VERSION "1.0.0"

NS_ :

BS_:

BU_: CVC FZC RZC SC BCM ICU TCU Diag

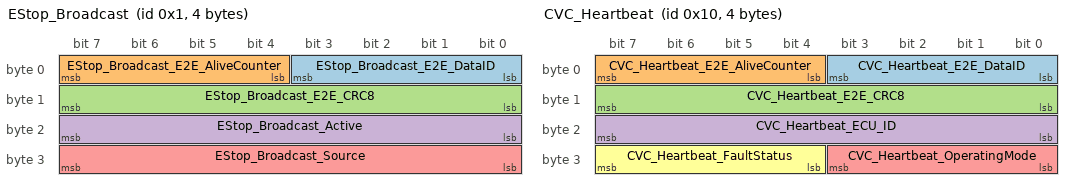
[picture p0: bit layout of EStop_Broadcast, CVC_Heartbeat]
BO_ 1 EStop_Broadcast: 4 CVC
 SG_ EStop_Broadcast_E2E_DataID : 0|4@1+ (1,0) [0|15] "" SC,FZC,RZC,BCM,ICU,TCU
 SG_ EStop_Broadcast_E2E_AliveCounter : 4|4@1+ (1,0) [0|15] "" SC,FZC,RZC,BCM,ICU,TCU
 SG_ EStop_Broadcast_E2E_CRC8 : 8|8@1+ (1,0) [0|255] "" SC,FZC,RZC,BCM,ICU,TCU
 SG_ EStop_Broadcast_Active : 16|8@1+ (1,0) [0|1] "" SC,FZC,RZC,BCM,ICU
 SG_ EStop_Broadcast_Source : 24|8@1+ (1,0) [0|7] "" SC,FZC,RZC,BCM,ICU

BO_ 16 CVC_Heartbeat: 4 CVC
 SG_ CVC_Heartbeat_E2E_DataID : 0|4@1+ (1,0) [0|15] "" SC,FZC,RZC,ICU
 SG_ CVC_Heartbeat_E2E_AliveCounter : 4|4@1+ (1,0) [0|15] "" SC,FZC,RZC,ICU
 SG_ CVC_Heartbeat_E2E_CRC8 : 8|8@1+ (1,0) [0|255] "" SC,FZC,RZC,ICU
 SG_ CVC_Heartbeat_ECU_ID : 16|8@1+ (1,0) [0|7] "" SC,FZC,RZC,ICU
 SG_ CVC_Heartbeat_OperatingMode : 24|4@1+ (1,0) [0|5] "" SC,FZC,RZC,ICU
 SG_ CVC_Heartbeat_FaultStatus : 28|4@1+ (1,0) [0|15] "" SC,FZC,RZC,ICU

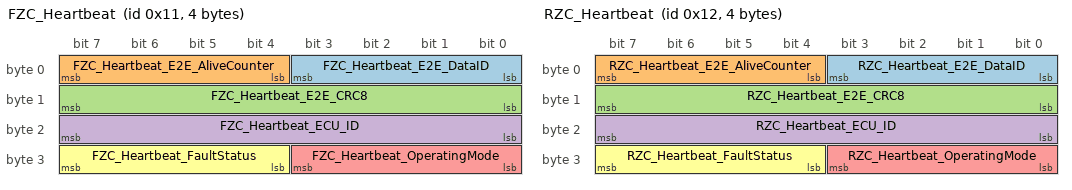
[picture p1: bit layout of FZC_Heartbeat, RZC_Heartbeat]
BO_ 17 FZC_Heartbeat: 4 FZC
 SG_ FZC_Heartbeat_E2E_DataID : 0|4@1+ (1,0) [0|15] "" SC,CVC,ICU
 SG_ FZC_Heartbeat_E2E_AliveCounter : 4|4@1+ (1,0) [0|15] "" SC,CVC,ICU
 SG_ FZC_Heartbeat_E2E_CRC8 : 8|8@1+ (1,0) [0|255] "" SC,CVC,ICU
 SG_ FZC_Heartbeat_ECU_ID : 16|8@1+ (1,0) [0|7] "" SC,CVC,ICU
 SG_ FZC_Heartbeat_OperatingMode : 24|4@1+ (1,0) [0|5] "" SC,CVC,ICU
 SG_ FZC_Heartbeat_FaultStatus : 28|4@1+ (1,0) [0|15] "" SC,CVC,ICU

BO_ 18 RZC_Heartbeat: 4 RZC
 SG_ RZC_Heartbeat_E2E_DataID : 0|4@1+ (1,0) [0|15] "" SC,CVC,ICU
 SG_ RZC_Heartbeat_E2E_AliveCounter : 4|4@1+ (1,0) [0|15] "" SC,CVC,ICU
 SG_ RZC_Heartbeat_E2E_CRC8 : 8|8@1+ (1,0) [0|255] "" SC,CVC,ICU
 SG_ RZC_Heartbeat_ECU_ID : 16|8@1+ (1,0) [0|7] "" SC,CVC,ICU
 SG_ RZC_Heartbeat_OperatingMode : 24|4@1+ (1,0) [0|5] "" SC,CVC,ICU
 SG_ RZC_Heartbeat_FaultStatus : 28|4@1+ (1,0) [0|15] "" SC,CVC,ICU

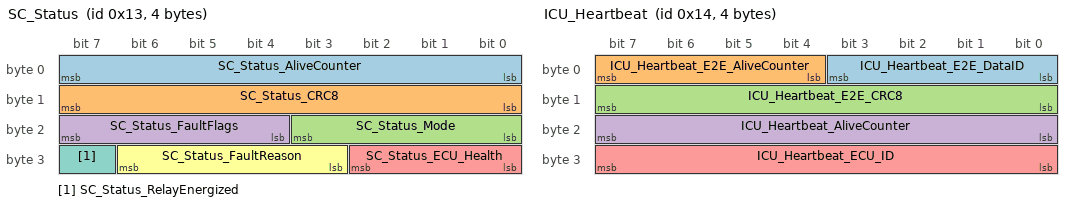
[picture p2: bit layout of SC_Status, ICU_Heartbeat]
BO_ 19 SC_Status: 4 SC
 SG_ SC_Status_AliveCounter : 0|8@1+ (1,0) [0|255] "" CVC,FZC,RZC,ICU
 SG_ SC_Status_CRC8 : 8|8@1+ (1,0) [0|255] "" CVC,FZC,RZC,ICU
 SG_ SC_Status_Mode : 16|4@1+ (1,0) [0|3] "" CVC,FZC,RZC,ICU
 SG_ SC_Status_FaultFlags : 20|4@1+ (1,0) [0|15] "" CVC,FZC,RZC,ICU
 SG_ SC_Status_ECU_Health : 24|3@1+ (1,0) [0|7] "" CVC,FZC,RZC,ICU
 SG_ SC_Status_FaultReason : 27|4@1+ (1,0) [0|15] "" CVC,FZC,RZC,ICU
 SG_ SC_Status_RelayEnergized : 31|1@1+ (1,0) [0|1] "" CVC,FZC,RZC,ICU

BO_ 20 ICU_Heartbeat: 4 ICU
 SG_ ICU_Heartbeat_E2E_DataID : 0|4@1+ (1,0) [0|15] "" CVC
 SG_ ICU_Heartbeat_E2E_AliveCounter : 4|4@1+ (1,0) [0|15] "" CVC
 SG_ ICU_Heartbeat_E2E_CRC8 : 8|8@1+ (1,0) [0|255] "" CVC
 SG_ ICU_Heartbeat_AliveCounter : 16|8@1+ (1,0) [0|255] "" CVC
 SG_ ICU_Heartbeat_ECU_ID : 24|8@1+ (1,0) [0|7] "" CVC

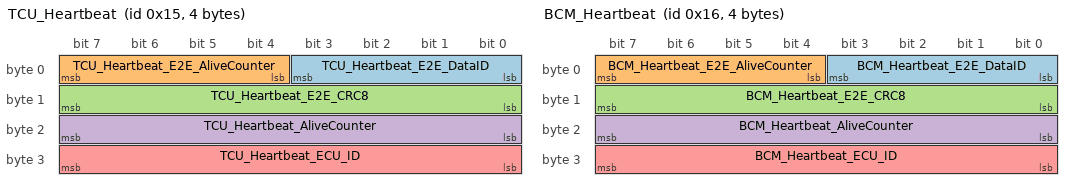
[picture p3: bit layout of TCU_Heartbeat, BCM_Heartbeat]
BO_ 21 TCU_Heartbeat: 4 TCU
 SG_ TCU_Heartbeat_E2E_DataID : 0|4@1+ (1,0) [0|15] "" CVC
 SG_ TCU_Heartbeat_E2E_AliveCounter : 4|4@1+ (1,0) [0|15] "" CVC
 SG_ TCU_Heartbeat_E2E_CRC8 : 8|8@1+ (1,0) [0|255] "" CVC
 SG_ TCU_Heartbeat_AliveCounter : 16|8@1+ (1,0) [0|255] "" CVC
 SG_ TCU_Heartbeat_ECU_ID : 24|8@1+ (1,0) [0|7] "" CVC

BO_ 22 BCM_Heartbeat: 4 BCM
 SG_ BCM_Heartbeat_E2E_DataID : 0|4@1+ (1,0) [0|15] "" CVC,ICU
 SG_ BCM_Heartbeat_E2E_AliveCounter : 4|4@1+ (1,0) [0|15] "" CVC,ICU
 SG_ BCM_Heartbeat_E2E_CRC8 : 8|8@1+ (1,0) [0|255] "" CVC,ICU
 SG_ BCM_Heartbeat_AliveCounter : 16|8@1+ (1,0) [0|255] "" CVC,ICU
 SG_ BCM_Heartbeat_ECU_ID : 24|8@1+ (1,0) [0|7] "" CVC,ICU

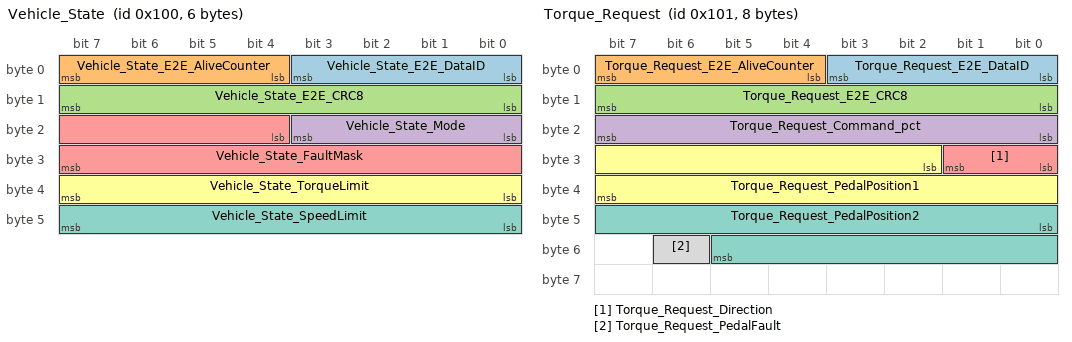
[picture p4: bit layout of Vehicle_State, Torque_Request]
BO_ 256 Vehicle_State: 6 CVC
 SG_ Vehicle_State_E2E_DataID : 0|4@1+ (1,0) [0|15] "" FZC,RZC,BCM,ICU,SC
 SG_ Vehicle_State_E2E_AliveCounter : 4|4@1+ (1,0) [0|15] "" FZC,RZC,BCM,ICU,SC
 SG_ Vehicle_State_E2E_CRC8 : 8|8@1+ (1,0) [0|255] "" FZC,RZC,BCM,ICU,SC
 SG_ Vehicle_State_Mode : 16|4@1+ (1,0) [0|5] "" FZC,RZC,BCM,ICU,SC
 SG_ Vehicle_State_FaultMask : 20|12@1+ (1,0) [0|4095] "" FZC,RZC,BCM,ICU,SC
 SG_ Vehicle_State_TorqueLimit : 32|8@1+ (1,0) [0|100] "%" RZC,ICU
 SG_ Vehicle_State_SpeedLimit : 40|8@1+ (1,0) [0|100] "%" RZC,ICU

BO_ 257 Torque_Request: 8 CVC
 SG_ Torque_Request_E2E_DataID : 0|4@1+ (1,0) [0|15] "" RZC
 SG_ Torque_Request_E2E_AliveCounter : 4|4@1+ (1,0) [0|15] "" RZC
 SG_ Torque_Request_E2E_CRC8 : 8|8@1+ (1,0) [0|255] "" RZC
 SG_ Torque_Request_Command_pct : 16|8@1+ (1,0) [0|100] "%" RZC
 SG_ Torque_Request_Direction : 24|2@1+ (1,0) [0|2] "" RZC
 SG_ Torque_Request_PedalPosition1 : 26|14@1+ (0.022,0) [0|359.98] "deg" RZC
 SG_ Torque_Request_PedalPosition2 : 40|14@1+ (0.022,0) [0|359.98] "deg" RZC
 SG_ Torque_Request_PedalFault : 54|1@1+ (1,0) [0|1] "" RZC

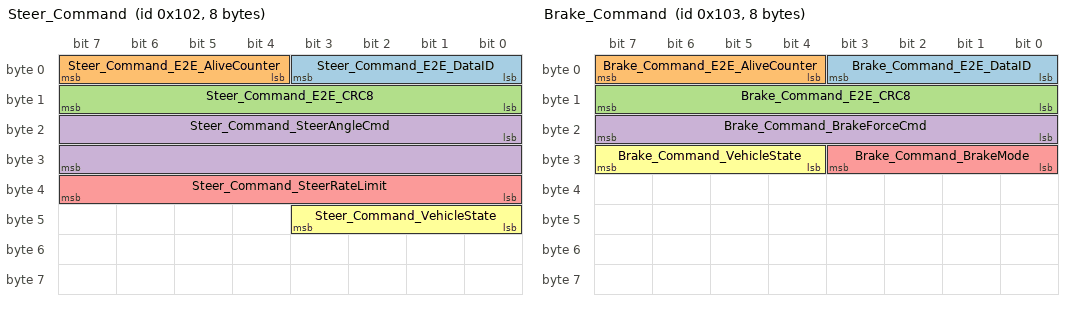
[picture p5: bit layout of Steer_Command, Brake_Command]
BO_ 258 Steer_Command: 8 CVC
 SG_ Steer_Command_E2E_DataID : 0|4@1+ (1,0) [0|15] "" FZC
 SG_ Steer_Command_E2E_AliveCounter : 4|4@1+ (1,0) [0|15] "" FZC
 SG_ Steer_Command_E2E_CRC8 : 8|8@1+ (1,0) [0|255] "" FZC
 SG_ Steer_Command_SteerAngleCmd : 16|16@1- (0.01,0) [-45.0|45.0] "deg" FZC
 SG_ Steer_Command_SteerRateLimit : 32|8@1+ (0.2,0) [0|51.0] "deg/s" FZC
 SG_ Steer_Command_VehicleState : 40|4@1+ (1,0) [0|5] "" FZC

BO_ 259 Brake_Command: 8 CVC
 SG_ Brake_Command_E2E_DataID : 0|4@1+ (1,0) [0|15] "" FZC
 SG_ Brake_Command_E2E_AliveCounter : 4|4@1+ (1,0) [0|15] "" FZC
 SG_ Brake_Command_E2E_CRC8 : 8|8@1+ (1,0) [0|255] "" FZC
 SG_ Brake_Command_BrakeForceCmd : 16|8@1+ (1,0) [0|100] "%" FZC
 SG_ Brake_Command_BrakeMode : 24|4@1+ (1,0) [0|3] "" FZC
 SG_ Brake_Command_VehicleState : 28|4@1+ (1,0) [0|5] "" FZC

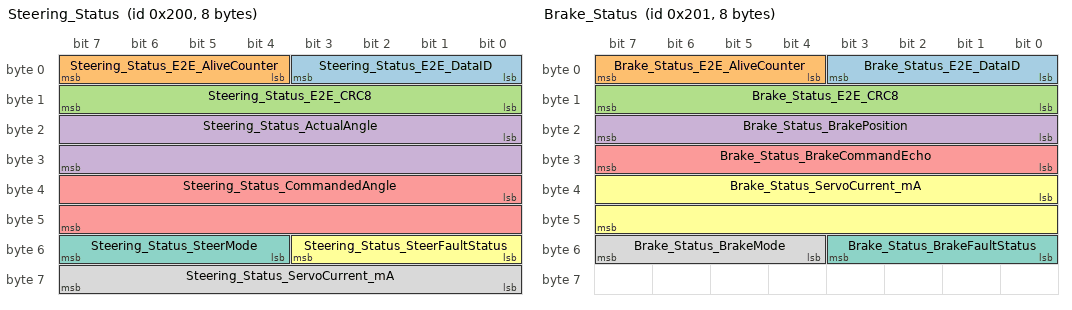
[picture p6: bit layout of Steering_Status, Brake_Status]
BO_ 512 Steering_Status: 8 FZC
 SG_ Steering_Status_E2E_DataID : 0|4@1+ (1,0) [0|15] "" CVC,SC,ICU
 SG_ Steering_Status_E2E_AliveCounter : 4|4@1+ (1,0) [0|15] "" CVC,SC,ICU
 SG_ Steering_Status_E2E_CRC8 : 8|8@1+ (1,0) [0|255] "" CVC,SC,ICU
 SG_ Steering_Status_ActualAngle : 16|16@1- (1,0) [-45|45] "deg" CVC,SC,ICU
 SG_ Steering_Status_CommandedAngle : 32|16@1- (1,0) [-45|45] "deg" CVC,SC,ICU
 SG_ Steering_Status_SteerFaultStatus : 48|4@1+ (1,0) [0|15] "" CVC,SC,ICU
 SG_ Steering_Status_SteerMode : 52|4@1+ (1,0) [0|3] "" CVC,SC,ICU
 SG_ Steering_Status_ServoCurrent_mA : 56|8@1+ (10,0) [0|2550] "mA" CVC,SC,ICU

BO_ 513 Brake_Status: 8 FZC
 SG_ Brake_Status_E2E_DataID : 0|4@1+ (1,0) [0|15] "" CVC,SC,ICU
 SG_ Brake_Status_E2E_AliveCounter : 4|4@1+ (1,0) [0|15] "" CVC,SC,ICU
 SG_ Brake_Status_E2E_CRC8 : 8|8@1+ (1,0) [0|255] "" CVC,SC,ICU
 SG_ Brake_Status_BrakePosition : 16|8@1+ (1,0) [0|100] "%" CVC,SC,ICU
 SG_ Brake_Status_BrakeCommandEcho : 24|8@1+ (1,0) [0|100] "%" CVC,SC,ICU
 SG_ Brake_Status_ServoCurrent_mA : 32|16@1+ (1,0) [0|3000] "mA" CVC,SC,ICU
 SG_ Brake_Status_BrakeFaultStatus : 48|4@1+ (1,0) [0|15] "" CVC,SC,ICU
 SG_ Brake_Status_BrakeMode : 52|4@1+ (1,0) [0|3] "" CVC,SC,ICU

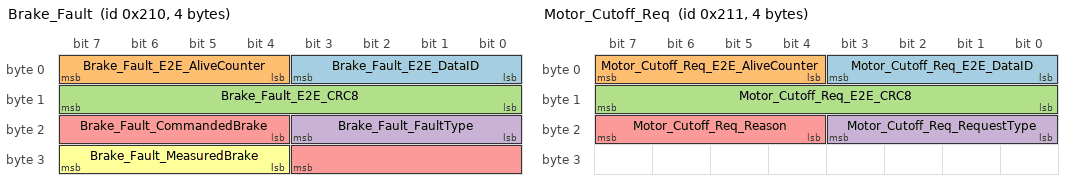
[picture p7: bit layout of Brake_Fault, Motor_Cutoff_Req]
BO_ 528 Brake_Fault: 4 FZC
 SG_ Brake_Fault_E2E_DataID : 0|4@1+ (1,0) [0|15] "" CVC,SC
 SG_ Brake_Fault_E2E_AliveCounter : 4|4@1+ (1,0) [0|15] "" CVC,SC
 SG_ Brake_Fault_E2E_CRC8 : 8|8@1+ (1,0) [0|255] "" CVC,SC
 SG_ Brake_Fault_FaultType : 16|4@1+ (1,0) [0|3] "" CVC,SC
 SG_ Brake_Fault_CommandedBrake : 20|8@1+ (1,0) [0|100] "%" CVC,SC
 SG_ Brake_Fault_MeasuredBrake : 28|4@1+ (10,0) [0|100] "%" CVC,SC

BO_ 529 Motor_Cutoff_Req: 4 FZC
 SG_ Motor_Cutoff_Req_E2E_DataID : 0|4@1+ (1,0) [0|15] "" CVC
 SG_ Motor_Cutoff_Req_E2E_AliveCounter : 4|4@1+ (1,0) [0|15] "" CVC
 SG_ Motor_Cutoff_Req_E2E_CRC8 : 8|8@1+ (1,0) [0|255] "" CVC
 SG_ Motor_Cutoff_Req_RequestType : 16|4@1+ (1,0) [0|3] "" CVC
 SG_ Motor_Cutoff_Req_Reason : 20|4@1+ (1,0) [0|7] "" CVC

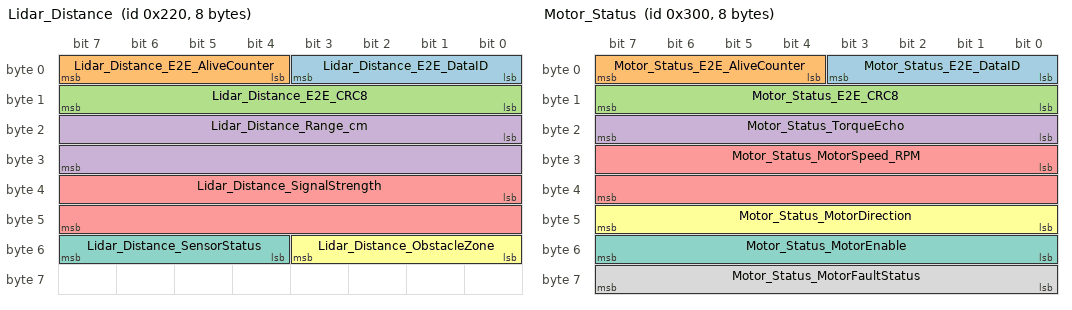
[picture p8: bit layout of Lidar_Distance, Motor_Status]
BO_ 544 Lidar_Distance: 8 FZC
 SG_ Lidar_Distance_E2E_DataID : 0|4@1+ (1,0) [0|15] "" CVC,ICU
 SG_ Lidar_Distance_E2E_AliveCounter : 4|4@1+ (1,0) [0|15] "" CVC,ICU
 SG_ Lidar_Distance_E2E_CRC8 : 8|8@1+ (1,0) [0|255] "" CVC,ICU
 SG_ Lidar_Distance_Range_cm : 16|16@1+ (1,0) [0|1200] "cm" CVC,ICU
 SG_ Lidar_Distance_SignalStrength : 32|16@1+ (1,0) [0|65535] "" CVC,ICU
 SG_ Lidar_Distance_ObstacleZone : 48|4@1+ (1,0) [0|3] "" CVC,ICU
 SG_ Lidar_Distance_SensorStatus : 52|4@1+ (1,0) [0|15] "" CVC,ICU

BO_ 768 Motor_Status: 8 RZC
 SG_ Motor_Status_E2E_DataID : 0|4@1+ (1,0) [0|15] "" CVC,SC,ICU
 SG_ Motor_Status_E2E_AliveCounter : 4|4@1+ (1,0) [0|15] "" CVC,SC,ICU
 SG_ Motor_Status_E2E_CRC8 : 8|8@1+ (1,0) [0|255] "" CVC,SC,ICU
 SG_ Motor_Status_TorqueEcho : 16|8@1+ (1,0) [0|100] "%" CVC,SC,ICU
 SG_ Motor_Status_MotorSpeed_RPM : 24|16@1+ (1,0) [0|10000] "RPM" CVC,SC,ICU
 SG_ Motor_Status_MotorDirection : 40|8@1+ (1,0) [0|2] "" CVC,SC,ICU
 SG_ Motor_Status_MotorEnable : 48|8@1+ (1,0) [0|1] "" CVC,SC,ICU
 SG_ Motor_Status_MotorFaultStatus : 56|8@1+ (1,0) [0|31] "" CVC,SC,ICU

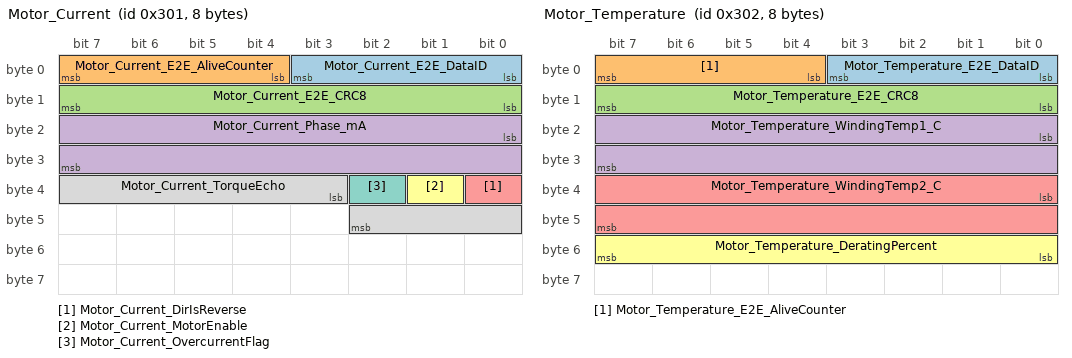
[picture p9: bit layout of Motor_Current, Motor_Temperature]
BO_ 769 Motor_Current: 8 RZC
 SG_ Motor_Current_E2E_DataID : 0|4@1+ (1,0) [0|15] "" SC,CVC,ICU
 SG_ Motor_Current_E2E_AliveCounter : 4|4@1+ (1,0) [0|15] "" SC,CVC,ICU
 SG_ Motor_Current_E2E_CRC8 : 8|8@1+ (1,0) [0|255] "" SC,CVC,ICU
 SG_ Motor_Current_Phase_mA : 16|16@1+ (1,0) [0|30000] "mA" SC,CVC,ICU
 SG_ Motor_Current_DirIsReverse : 32|1@1+ (1,0) [0|1] "" SC,CVC,ICU
 SG_ Motor_Current_MotorEnable : 33|1@1+ (1,0) [0|1] "" SC,CVC,ICU
 SG_ Motor_Current_OvercurrentFlag : 34|1@1+ (1,0) [0|1] "" SC,CVC,ICU
 SG_ Motor_Current_TorqueEcho : 35|8@1+ (1,0) [0|100] "%" SC,CVC,ICU

BO_ 770 Motor_Temperature: 8 RZC
 SG_ Motor_Temperature_E2E_DataID : 0|4@1+ (1,0) [0|15] "" CVC,ICU
 SG_ Motor_Temperature_E2E_AliveCounter : 4|4@1+ (1,0) [0|15] "" CVC,ICU
 SG_ Motor_Temperature_E2E_CRC8 : 8|8@1+ (1,0) [0|255] "" CVC,ICU
 SG_ Motor_Temperature_WindingTemp1_C : 16|16@1+ (0.1,0) [0|200.0] "degC" CVC,ICU
 SG_ Motor_Temperature_WindingTemp2_C : 32|16@1+ (0.1,0) [0|200.0] "degC" CVC,ICU
 SG_ Motor_Temperature_DeratingPercent : 48|8@1+ (1,0) [0|100] "%" CVC,ICU

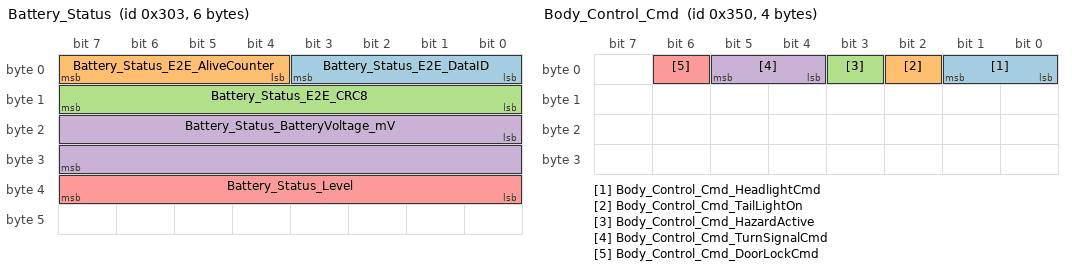
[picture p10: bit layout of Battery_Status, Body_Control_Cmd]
BO_ 771 Battery_Status: 6 RZC
 SG_ Battery_Status_E2E_DataID : 0|4@1+ (1,0) [0|15] "" CVC,ICU
 SG_ Battery_Status_E2E_AliveCounter : 4|4@1+ (1,0) [0|15] "" CVC,ICU
 SG_ Battery_Status_E2E_CRC8 : 8|8@1+ (1,0) [0|255] "" CVC,ICU
 SG_ Battery_Status_BatteryVoltage_mV : 16|16@1+ (1,0) [0|20000] "mV" CVC,ICU
 SG_ Battery_Status_Level : 32|8@1+ (1,0) [0|4] "" CVC,ICU

BO_ 848 Body_Control_Cmd: 4 CVC
 SG_ Body_Control_Cmd_HeadlightCmd : 0|2@1+ (1,0) [0|2] "" BCM
 SG_ Body_Control_Cmd_TailLightOn : 2|1@1+ (1,0) [0|1] "" BCM
 SG_ Body_Control_Cmd_HazardActive : 3|1@1+ (1,0) [0|1] "" BCM
 SG_ Body_Control_Cmd_TurnSignalCmd : 4|2@1+ (1,0) [0|2] "" BCM
 SG_ Body_Control_Cmd_DoorLockCmd : 6|1@1+ (1,0) [0|1] "" BCM

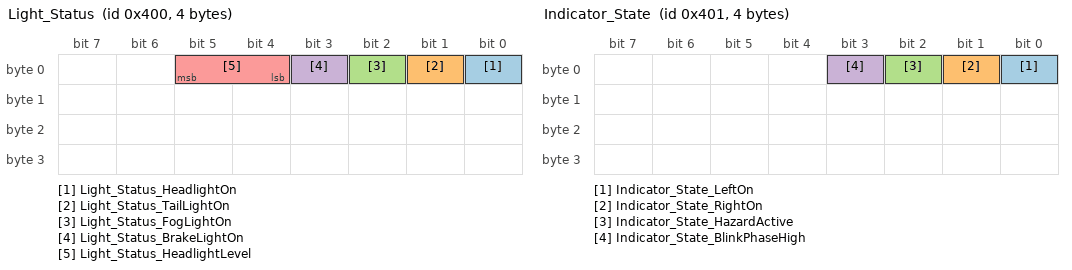
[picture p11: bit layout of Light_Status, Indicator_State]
BO_ 1024 Light_Status: 4 BCM
 SG_ Light_Status_HeadlightOn : 0|1@1+ (1,0) [0|1] "" ICU
 SG_ Light_Status_TailLightOn : 1|1@1+ (1,0) [0|1] "" ICU
 SG_ Light_Status_FogLightOn : 2|1@1+ (1,0) [0|1] "" ICU
 SG_ Light_Status_BrakeLightOn : 3|1@1+ (1,0) [0|1] "" ICU
 SG_ Light_Status_HeadlightLevel : 4|2@1+ (1,0) [0|2] "" ICU

BO_ 1025 Indicator_State: 4 BCM
 SG_ Indicator_State_LeftOn : 0|1@1+ (1,0) [0|1] "" ICU
 SG_ Indicator_State_RightOn : 1|1@1+ (1,0) [0|1] "" ICU
 SG_ Indicator_State_HazardActive : 2|1@1+ (1,0) [0|1] "" ICU
 SG_ Indicator_State_BlinkPhaseHigh : 3|1@1+ (1,0) [0|1] "" ICU

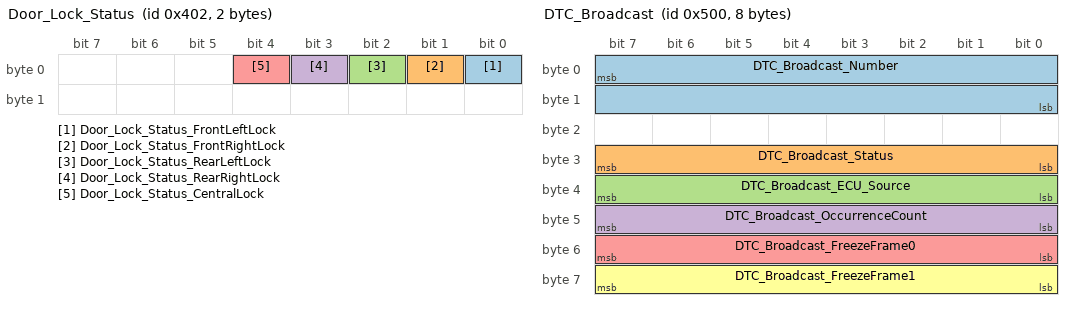
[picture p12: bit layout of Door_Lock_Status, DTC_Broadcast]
BO_ 1026 Door_Lock_Status: 2 BCM
 SG_ Door_Lock_Status_FrontLeftLock : 0|1@1+ (1,0) [0|1] "" ICU
 SG_ Door_Lock_Status_FrontRightLock : 1|1@1+ (1,0) [0|1] "" ICU
 SG_ Door_Lock_Status_RearLeftLock : 2|1@1+ (1,0) [0|1] "" ICU
 SG_ Door_Lock_Status_RearRightLock : 3|1@1+ (1,0) [0|1] "" ICU
 SG_ Door_Lock_Status_CentralLock : 4|1@1+ (1,0) [0|1] "" ICU

BO_ 1280 DTC_Broadcast: 8 CVC
 SG_ DTC_Broadcast_Number : 7|16@0+ (1,0) [0|65535] "" TCU,ICU
 SG_ DTC_Broadcast_Status : 24|8@1+ (1,0) [0|255] "" TCU,ICU
 SG_ DTC_Broadcast_ECU_Source : 32|8@1+ (1,0) [0|7] "" TCU,ICU
 SG_ DTC_Broadcast_OccurrenceCount : 40|8@1+ (1,0) [0|255] "" TCU,ICU
 SG_ DTC_Broadcast_FreezeFrame0 : 48|8@1+ (1,0) [0|255] "" TCU,ICU
 SG_ DTC_Broadcast_FreezeFrame1 : 56|8@1+ (1,0) [0|255] "" TCU,ICU

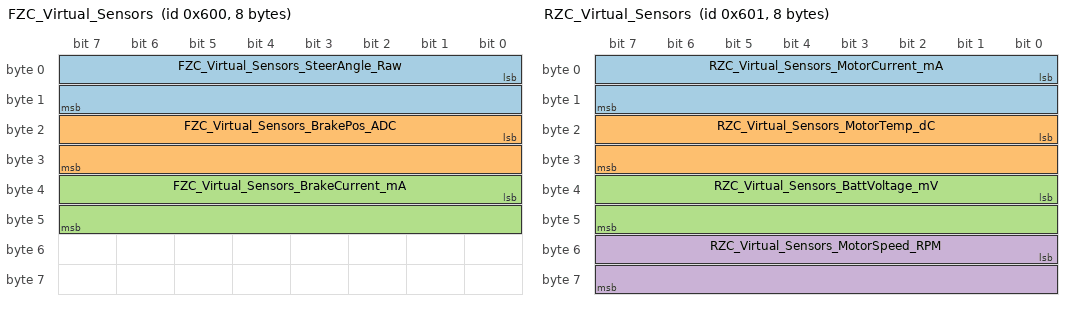
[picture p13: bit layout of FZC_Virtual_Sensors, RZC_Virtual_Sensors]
BO_ 1536 FZC_Virtual_Sensors: 8 CVC
 SG_ FZC_Virtual_Sensors_SteerAngle_Raw : 0|16@1+ (1,0) [0|16383] "" FZC
 SG_ FZC_Virtual_Sensors_BrakePos_ADC : 16|16@1+ (1,0) [0|1000] "" FZC
 SG_ FZC_Virtual_Sensors_BrakeCurrent_mA : 32|16@1+ (1,0) [0|65535] "mA" FZC

BO_ 1537 RZC_Virtual_Sensors: 8 CVC
 SG_ RZC_Virtual_Sensors_MotorCurrent_mA : 0|16@1+ (1,0) [0|65535] "mA" RZC
 SG_ RZC_Virtual_Sensors_MotorTemp_dC : 16|16@1+ (1,0) [0|2000] "" RZC
 SG_ RZC_Virtual_Sensors_BattVoltage_mV : 32|16@1+ (1,0) [0|20000] "mV" RZC
 SG_ RZC_Virtual_Sensors_MotorSpeed_RPM : 48|16@1+ (1,0) [0|10000] "rpm" RZC

BO_ 1604 UDS_Resp_TCU: 8 TCU
 SG_ UDS_Resp_TCU_UDS_Data : 0|64@1+ (1,0) [0|0] "" Diag

BO_ 2015 UDS_Func_Request: 8 Diag
 SG_ UDS_Func_Request_UDS_Data : 0|64@1+ (1,0) [0|0] "" CVC,FZC,RZC,TCU,BCM,ICU

BO_ 2016 UDS_Phys_Req_CVC: 8 Diag
 SG_ UDS_Phys_Req_CVC_UDS_Data : 0|64@1+ (1,0) [0|0] "" CVC

BO_ 2017 UDS_Phys_Req_FZC: 8 Diag
 SG_ UDS_Phys_Req_FZC_UDS_Data : 0|64@1+ (1,0) [0|0] "" FZC

BO_ 2018 UDS_Phys_Req_RZC: 8 Diag
 SG_ UDS_Phys_Req_RZC_UDS_Data : 0|64@1+ (1,0) [0|0] "" RZC

BO_ 2019 UDS_Phys_Req_TCU: 8 Diag
 SG_ UDS_Phys_Req_TCU_UDS_Data : 0|64@1+ (1,0) [0|0] "" TCU

BO_ 2024 UDS_Resp_CVC: 8 CVC
 SG_ UDS_Resp_CVC_UDS_Data : 0|64@1+ (1,0) [0|0] "" Diag

BO_ 2025 UDS_Resp_FZC: 8 FZC
 SG_ UDS_Resp_FZC_UDS_Data : 0|64@1+ (1,0) [0|0] "" Diag

BO_ 2026 UDS_Resp_RZC: 8 RZC
 SG_ UDS_Resp_RZC_UDS_Data : 0|64@1+ (1,0) [0|0] "" Diag

BO_ 1360 XCP_Req_CVC: 8 Diag
 SG_ XCP_Req_CVC_Data : 0|64@1+ (1,0) [0|0] "" CVC

BO_ 1361 XCP_Resp_CVC: 8 CVC
 SG_ XCP_Resp_CVC_Data : 0|64@1+ (1,0) [0|0] "" Diag

BO_ 1362 XCP_Req_FZC: 8 Diag
 SG_ XCP_Req_FZC_Data : 0|64@1+ (1,0) [0|0] "" FZC

BO_ 1363 XCP_Resp_FZC: 8 FZC
 SG_ XCP_Resp_FZC_Data : 0|64@1+ (1,0) [0|0] "" Diag

BO_ 1364 XCP_Req_RZC: 8 Diag
 SG_ XCP_Req_RZC_Data : 0|64@1+ (1,0) [0|0] "" RZC

BO_ 1365 XCP_Resp_RZC: 8 RZC
 SG_ XCP_Resp_RZC_Data : 0|64@1+ (1,0) [0|0] "" Diag

BO_ 1366 XCP_Req_SC: 8 Diag
 SG_ XCP_Req_SC_Data : 0|64@1+ (1,0) [0|0] "" SC

BO_ 1367 XCP_Resp_SC: 8 SC
 SG_ XCP_Resp_SC_Data : 0|64@1+ (1,0) [0|0] "" Diag

CM_ BU_ CVC "Central Vehicle Computer. STM32F446RE. ASIL D. Master coordinator.";
CM_ BU_ FZC "Front Zone Controller. STM32F446RE. ASIL D. Steering, braking, lidar.";
CM_ BU_ RZC "Rear Zone Controller. STM32F446RE. ASIL C. Motor, battery, encoder.";
CM_ BU_ SC "Safety Controller. TMS570LS0432. ASIL D. Independent relay watchdog.";
CM_ BU_ BCM "Body Control Module. Docker SIL. QM. Lights, indicators, locks.";
CM_ BU_ ICU "Instrument Cluster Unit. Docker SIL. QM. Display, DTC viewer.";
CM_ BU_ TCU "Telematics Control Unit. Docker SIL. QM. UDS server, data logging.";
CM_ BU_ Diag "Diagnostic interface. OBD-II port. ISO 14229. External tester connection.";

CM_ BO_ 1 "Emergency stop broadcast. Event-triggered + 10ms repeat x4. ASIL B.";
CM_ BO_ 16 "CVC heartbeat. 50ms cyclic. SC monitors alive counter for timeout.";
CM_ BO_ 17 "FZC heartbeat. 50ms cyclic. SC monitors alive counter for timeout.";
CM_ BO_ 18 "RZC heartbeat. 50ms cyclic. SC monitors alive counter for timeout.";
CM_ BO_ 19 "SC status. 500ms cyclic. Simplified E2E (8-bit counter + CRC-8).";
CM_ BO_ 20 "ICU heartbeat. 500ms cyclic. QM — no safety monitoring.";
CM_ BO_ 21 "TCU heartbeat. 500ms cyclic. QM — no safety monitoring.";
CM_ BO_ 22 "BCM heartbeat. 500ms cyclic. QM — no safety monitoring.";
CM_ BO_ 256 "Vehicle state. 10ms cyclic. Contains VSM state + fault mask + limits.";
CM_ BO_ 257 "Torque request. 10ms cyclic. CVC to RZC. ASIL D safety path.";
CM_ BO_ 258 "Steering command. 10ms cyclic. CVC to FZC. ASIL D safety path.";
CM_ BO_ 259 "Brake command. 10ms cyclic. CVC to FZC. ASIL D safety path.";
CM_ BO_ 512 "Steering status. 20ms cyclic. FZC feedback to CVC.";
CM_ BO_ 513 "Brake status. 20ms cyclic. FZC feedback to CVC.";
CM_ BO_ 528 "Brake fault event. FZC to CVC + SC. ASIL D.";
CM_ BO_ 529 "Motor cutoff request. FZC to CVC. Event + 10ms repeat.";
CM_ BO_ 544 "Lidar distance. 10ms cyclic. TFMini-S sensor via FZC.";
CM_ BO_ 768 "Motor status. 20ms cyclic. RZC encoder speed + fault status.";
CM_ BO_ 769 "Motor current. 10ms cyclic. ACS723 current sensor via RZC.";
CM_ BO_ 770 "Motor temperature. 100ms cyclic. NTC thermistor via RZC.";
CM_ BO_ 771 "Battery status. 1000ms cyclic. Voltage divider ADC via RZC.";
CM_ BO_ 848 "Body control command. 100ms cyclic. CVC to BCM.";
CM_ BO_ 1024 "Light status. 100ms cyclic. BCM feedback.";
CM_ BO_ 1025 "Indicator state. 100ms cyclic. BCM feedback.";
CM_ BO_ 1026 "Door lock status. Event-triggered. BCM feedback.";
CM_ BO_ 1280 "DTC broadcast. Event-triggered. Any ECU via Dem_MainFunction.";
CM_ BO_ 1536 "FZC virtual sensors. 10ms cyclic. Replaces SPI/ADC on SIL. No E2E.";
CM_ BO_ 1537 "RZC virtual sensors. 10ms cyclic. Replaces ADC on SIL. No E2E.";
CM_ BO_ 1604 "UDS response from TCU. ISO 14229.";
CM_ BO_ 2015 "UDS functional request. ISO 14229. Broadcast to all ECUs.";
CM_ BO_ 2016 "UDS physical request to CVC. ISO 14229.";
CM_ BO_ 2017 "UDS physical request to FZC. ISO 14229.";
CM_ BO_ 2018 "UDS physical request to RZC. ISO 14229.";
CM_ BO_ 2019 "UDS physical request to TCU. ISO 14229.";
CM_ BO_ 2024 "UDS response from CVC. ISO 14229.";
CM_ BO_ 2025 "UDS response from FZC. ISO 14229.";
CM_ BO_ 2026 "UDS response from RZC. ISO 14229.";
CM_ BO_ 1360 "XCP request to CVC. ASAM MCD-1 XCP on CAN. Measurement and calibration.";
CM_ BO_ 1361 "XCP response from CVC.";
CM_ BO_ 1362 "XCP request to FZC.";
CM_ BO_ 1363 "XCP response from FZC.";
CM_ BO_ 1364 "XCP request to RZC.";
CM_ BO_ 1365 "XCP response from RZC.";
CM_ BO_ 1366 "XCP request to SC.";
CM_ BO_ 1367 "XCP response from SC.";

CM_ SG_ 1 EStop_Broadcast_Active "1=E-Stop active (latched until power-cycle). 0=inactive.";
CM_ SG_ 1 EStop_Broadcast_Source "Source that triggered E-Stop. 0=button, 1=CAN, 2=SC_relay.";
CM_ SG_ 256 Vehicle_State_Mode "VSM state. 0=INIT, 1=RUN, 2=DEGRADED, 3=LIMP, 4=SAFE_STOP, 5=SHUTDOWN.";
CM_ SG_ 256 Vehicle_State_FaultMask "Bitmask of active faults. Bit0=EStop, Bit1=SC_Kill, Bit2=MotorCutoff, etc.";
CM_ SG_ 257 Torque_Request_Command_pct "Torque command 0-100%. Maps to motor PWM duty cycle.";
CM_ SG_ 258 Steer_Command_SteerAngleCmd "Steering angle command. Signed, 0.01 deg resolution. 0=center.";
CM_ SG_ 259 Brake_Command_BrakeForceCmd "Brake force command 0-100%. Maps to brake servo PWM.";
CM_ SG_ 768 Motor_Status_MotorFaultStatus "Motor fault code. 0=OK, 1=stall, 2=shoot-through, 3=overcurrent, 4=overtemp.";
CM_ SG_ 768 Motor_Status_MotorSpeed_RPM "Encoder-derived motor speed in RPM. 0-10000.";
CM_ SG_ 769 Motor_Current_Phase_mA "Phase current in milliamps. ACS723 sensor. 0-30000.";
CM_ SG_ 769 Motor_Current_OvercurrentFlag "1=overcurrent detected (>25A sustained). Latched until recovery.";
CM_ SG_ 770 Motor_Temperature_WindingTemp1_C "Winding temperature sensor 1. 0.1 degC resolution. NTC thermistor.";
CM_ SG_ 771 Battery_Status_BatteryVoltage_mV "Battery voltage in millivolts. Voltage divider ADC. 0-20000.";
CM_ SG_ 771 Battery_Status_Level "Battery status enum. 0=critical_UV, 1=UV_warn, 2=normal, 3=OV_warn, 4=critical_OV.";
CM_ SG_ 1280 DTC_Broadcast_Number "16-bit UDS DTC number (big-endian). Standard ISO 14229 format.";
CM_ SG_ 1280 DTC_Broadcast_ECU_Source "Source ECU. 1=CVC, 2=FZC, 3=RZC, 4=SC, 5=BCM, 6=ICU, 7=TCU.";

VAL_ 1 EStop_Broadcast_Source 0 "CVC_button" 1 "CAN_request" 2 "SC_relay" ;
VAL_ 16 CVC_Heartbeat_OperatingMode 0 "INIT" 1 "RUN" 2 "DEGRADED" 3 "LIMP" 4 "SAFE_STOP" 5 "SHUTDOWN" ;
VAL_ 17 FZC_Heartbeat_OperatingMode 0 "INIT" 1 "RUN" 2 "DEGRADED" 3 "LIMP" 4 "SAFE_STOP" 5 "SHUTDOWN" ;
VAL_ 18 RZC_Heartbeat_OperatingMode 0 "INIT" 1 "RUN" 2 "DEGRADED" 3 "LIMP" 4 "SAFE_STOP" 5 "SHUTDOWN" ;
VAL_ 19 SC_Status_Mode 0 "INIT" 1 "MONITORING" 2 "FAULT_DETECTED" 3 "SAFE_STOP" ;
VAL_ 256 Vehicle_State_Mode 0 "INIT" 1 "RUN" 2 "DEGRADED" 3 "LIMP" 4 "SAFE_STOP" 5 "SHUTDOWN" ;
VAL_ 257 Torque_Request_Direction 0 "stopped" 1 "forward" 2 "reverse" ;
VAL_ 259 Brake_Command_BrakeMode 0 "release" 1 "normal" 2 "emergency" 3 "auto" ;
VAL_ 512 Steering_Status_SteerMode 0 "normal" 1 "return_center" 2 "disabled" 3 "local" ;
VAL_ 513 Brake_Status_BrakeMode 0 "release" 1 "normal" 2 "auto_brake" 3 "emergency" ;
VAL_ 528 Brake_Fault_FaultType 0 "PWM_mismatch" 1 "servo_stuck" 2 "overcurrent" 3 "timeout" ;
VAL_ 529 Motor_Cutoff_Req_RequestType 0 "motor_cutoff" 1 "speed_reduce" 2 "e_stop_fwd" ;
VAL_ 529 Motor_Cutoff_Req_Reason 0 "brake_fault" 1 "steer_fault" 2 "lidar_emergency" 3 "CAN_loss" ;
VAL_ 544 Lidar_Distance_ObstacleZone 0 "emergency" 1 "braking" 2 "warning" 3 "clear" ;
VAL_ 768 Motor_Status_MotorDirection 0 "stopped" 1 "forward" 2 "reverse" ;
VAL_ 769 Motor_Current_DirIsReverse 0 "forward" 1 "reverse" ;
VAL_ 771 Battery_Status_Level 0 "critical_UV" 1 "UV_warn" 2 "normal" 3 "OV_warn" 4 "critical_OV" ;
VAL_ 848 Body_Control_Cmd_HeadlightCmd 0 "off" 1 "low" 2 "high" ;
VAL_ 848 Body_Control_Cmd_TurnSignalCmd 0 "off" 1 "left" 2 "right" ;
VAL_ 1024 Light_Status_HeadlightLevel 0 "off" 1 "low" 2 "high" ;
VAL_ 1280 DTC_Broadcast_ECU_Source 1 "CVC" 2 "FZC" 3 "RZC" 4 "SC" 5 "BCM" 6 "ICU" 7 "TCU" ;

BA_DEF_ BO_ "GenMsgCycleTime" INT 0 10000;
BA_DEF_ BO_ "GenMsgSendType" STRING;
BA_DEF_ BO_ "ASIL" STRING;
BA_DEF_ BO_ "E2E_DataID" INT -1 255;
BA_DEF_ BO_ "Owner" STRING;
BA_DEF_ BO_ "Satisfies" STRING;
BA_DEF_ SG_ "Owner" STRING;
BA_DEF_ SG_ "Satisfies" STRING;
BA_DEF_ SG_ "GenSigStartValue" INT -32768 65535;
BA_DEF_ SG_ "ProducedBy" STRING;
BA_DEF_ SG_ "Timeout_ms" INT 0 10000;
BA_DEF_ BO_ "GenMsgCycleTimeFast" INT 0 10000;
BA_DEF_ BO_ "GenMsgNrOfRepetition" INT 0 10;
BA_DEF_ BO_ "E2E_MaxDeltaCounter" INT 0 15;
BA_DEF_ BO_ "E2E_Profile" STRING;
BA_DEF_ BO_ "Satisfies" STRING;

BA_DEF_DEF_ "GenMsgCycleTimeFast" 0;
BA_DEF_DEF_ "GenMsgNrOfRepetition" 0;
BA_DEF_DEF_ "E2E_MaxDeltaCounter" 2;
BA_DEF_DEF_ "E2E_Profile" "P01";
BA_DEF_DEF_ "Satisfies" "";

BA_ "GenMsgCycleTime" BO_ 1 10;
BA_ "GenMsgCycleTime" BO_ 16 50;
BA_ "GenMsgCycleTime" BO_ 17 50;
BA_ "GenMsgCycleTime" BO_ 18 50;
BA_ "GenMsgCycleTime" BO_ 19 100;
BA_ "GenMsgCycleTime" BO_ 20 500;
BA_ "GenMsgCycleTime" BO_ 21 500;
BA_ "GenMsgCycleTime" BO_ 22 500;
BA_ "GenMsgCycleTime" BO_ 256 10;
BA_ "GenMsgCycleTime" BO_ 257 10;
BA_ "GenMsgCycleTime" BO_ 258 10;
BA_ "GenMsgCycleTime" BO_ 259 10;
BA_ "GenMsgCycleTime" BO_ 512 50;
BA_ "GenMsgCycleTime" BO_ 513 50;
BA_ "GenMsgCycleTime" BO_ 528 0;
BA_ "GenMsgCycleTime" BO_ 529 50;
BA_ "GenMsgCycleTime" BO_ 544 10;
BA_ "GenMsgCycleTime" BO_ 768 100;
BA_ "GenMsgCycleTime" BO_ 769 100;
BA_ "GenMsgCycleTime" BO_ 770 100;
BA_ "GenMsgCycleTime" BO_ 771 1000;
BA_ "GenMsgCycleTime" BO_ 848 100;
BA_ "GenMsgCycleTime" BO_ 1024 100;
BA_ "GenMsgCycleTime" BO_ 1025 100;
BA_ "GenMsgCycleTime" BO_ 1026 0;
BA_ "GenMsgCycleTime" BO_ 1280 0;
BA_ "GenMsgSendType" BO_ 1 "event";
BA_ "GenMsgSendType" BO_ 16 "cyclic";
BA_ "GenMsgSendType" BO_ 17 "cyclic";
BA_ "GenMsgSendType" BO_ 18 "cyclic";
BA_ "GenMsgSendType" BO_ 19 "cyclic";
BA_ "GenMsgSendType" BO_ 20 "cyclic";
BA_ "GenMsgSendType" BO_ 21 "cyclic";
BA_ "GenMsgSendType" BO_ 22 "cyclic";
BA_ "GenMsgSendType" BO_ 256 "cyclic";
BA_ "GenMsgSendType" BO_ 257 "cyclic";
BA_ "GenMsgSendType" BO_ 258 "cyclic";
BA_ "GenMsgSendType" BO_ 259 "cyclic";
BA_ "GenMsgSendType" BO_ 512 "cyclic";
BA_ "GenMsgSendType" BO_ 513 "cyclic";
BA_ "GenMsgSendType" BO_ 528 "event";
BA_ "GenMsgSendType" BO_ 529 "event";
BA_ "GenMsgSendType" BO_ 544 "cyclic";
BA_ "GenMsgSendType" BO_ 768 "cyclic";
BA_ "GenMsgSendType" BO_ 769 "cyclic";
BA_ "GenMsgSendType" BO_ 770 "cyclic";
BA_ "GenMsgSendType" BO_ 771 "cyclic";
BA_ "GenMsgSendType" BO_ 848 "cyclic";
BA_ "GenMsgSendType" BO_ 1024 "cyclic";
BA_ "GenMsgSendType" BO_ 1025 "cyclic";
BA_ "GenMsgSendType" BO_ 1026 "event";
BA_ "GenMsgSendType" BO_ 1280 "event";
BA_ "ASIL" BO_ 1 "B";
BA_ "ASIL" BO_ 16 "C";
BA_ "ASIL" BO_ 17 "C";
BA_ "ASIL" BO_ 18 "C";
BA_ "ASIL" BO_ 19 "D";
BA_ "ASIL" BO_ 20 "QM";
BA_ "ASIL" BO_ 21 "QM";
BA_ "ASIL" BO_ 22 "QM";
BA_ "ASIL" BO_ 256 "D";
BA_ "ASIL" BO_ 257 "D";
BA_ "ASIL" BO_ 258 "D";
BA_ "ASIL" BO_ 259 "D";
BA_ "ASIL" BO_ 512 "D";
BA_ "ASIL" BO_ 513 "D";
BA_ "ASIL" BO_ 528 "D";
BA_ "ASIL" BO_ 529 "D";
BA_ "ASIL" BO_ 544 "C";
BA_ "ASIL" BO_ 768 "D";
BA_ "ASIL" BO_ 769 "C";
BA_ "ASIL" BO_ 770 "A";
BA_ "ASIL" BO_ 771 "QM";
BA_ "ASIL" BO_ 848 "QM";
BA_ "ASIL" BO_ 1024 "QM";
BA_ "ASIL" BO_ 1025 "QM";
BA_ "ASIL" BO_ 1026 "QM";
BA_ "ASIL" BO_ 1280 "QM";
BA_ "E2E_DataID" BO_ 1 1;
BA_ "E2E_DataID" BO_ 16 2;
BA_ "E2E_DataID" BO_ 17 3;
BA_ "E2E_DataID" BO_ 18 4;
BA_ "E2E_DataID" BO_ 256 5;
BA_ "E2E_DataID" BO_ 257 6;
BA_ "E2E_DataID" BO_ 258 7;
BA_ "E2E_DataID" BO_ 259 8;
BA_ "E2E_DataID" BO_ 512 9;
BA_ "E2E_DataID" BO_ 513 10;
BA_ "E2E_DataID" BO_ 528 11;
BA_ "E2E_DataID" BO_ 529 12;
BA_ "E2E_DataID" BO_ 544 13;
BA_ "E2E_DataID" BO_ 768 14;
BA_ "E2E_DataID" BO_ 769 15;
/* Motor_Temperature (770) and Battery_Status (771): no E2E DataID.
 * These use timeout-based monitoring only (ASIL A / ASIL C).
 * All 16 DataID slots (0-15) are already allocated. */
BA_ "Owner" BO_ 1 "CVC Application";
BA_ "Owner" BO_ 16 "CVC Application";
BA_ "Owner" BO_ 17 "FZC Application";
BA_ "Owner" BO_ 18 "RZC Application";
BA_ "Owner" BO_ 19 "SC Application";
BA_ "Owner" BO_ 20 "ICU Application";
BA_ "Owner" BO_ 21 "TCU Application";
BA_ "Owner" BO_ 22 "BCM Application";
BA_ "Owner" BO_ 256 "CVC Application";
BA_ "Owner" BO_ 257 "CVC Application";
BA_ "Owner" BO_ 258 "CVC Application";
BA_ "Owner" BO_ 259 "CVC Application";
BA_ "Owner" BO_ 512 "FZC Application";
BA_ "Owner" BO_ 513 "FZC Application";
BA_ "Owner" BO_ 528 "FZC Application";
BA_ "Owner" BO_ 529 "FZC Application";
BA_ "Owner" BO_ 544 "FZC Application";
BA_ "Owner" BO_ 768 "RZC Application";
BA_ "Owner" BO_ 769 "RZC Application";
BA_ "Owner" BO_ 770 "RZC Application";
BA_ "Owner" BO_ 771 "RZC Application";
BA_ "Owner" BO_ 848 "CVC Application";
BA_ "Owner" BO_ 1024 "BCM Application";
BA_ "Owner" BO_ 1025 "BCM Application";
BA_ "Owner" BO_ 1026 "BCM Application";
BA_ "Owner" BO_ 1280 "BSW Integration";
BA_ "Satisfies" BO_ 1 "TSR-046 FSR-001";
BA_ "Satisfies" BO_ 256 "TSR-022 FSR-001 FSR-002";
BA_ "Satisfies" BO_ 257 "TSR-023 SSR-CVC-001";
BA_ "Satisfies" BO_ 258 "TSR-024 SSR-CVC-002";
BA_ "Satisfies" BO_ 259 "TSR-025 SSR-CVC-003";
BA_ "Satisfies" BO_ 528 "TSR-030 SSR-FZC-005";
BA_ "Satisfies" BO_ 529 "TSR-031 SSR-FZC-006";
BA_ "Satisfies" BO_ 768 "TSR-032 SSR-RZC-001";
BA_ "Satisfies" BO_ 769 "TSR-033 SSR-RZC-002";
BA_ "Owner" SG_ 256 Vehicle_State_Mode "Swc_VehicleState";
BA_ "ProducedBy" SG_ 256 Vehicle_State_Mode "Swc_VehicleState";
BA_ "Satisfies" SG_ 256 Vehicle_State_Mode "SSR-CVC-010";
BA_ "GenSigStartValue" SG_ 256 Vehicle_State_Mode 0;
BA_ "Timeout_ms" SG_ 256 Vehicle_State_Mode 50;
BA_ "Owner" SG_ 256 Vehicle_State_FaultMask "Swc_CvcCom";
BA_ "ProducedBy" SG_ 256 Vehicle_State_FaultMask "Swc_CvcCom";
BA_ "GenSigStartValue" SG_ 256 Vehicle_State_FaultMask 0;
BA_ "Owner" SG_ 257 Torque_Request_Command_pct "Swc_Pedal";
BA_ "ProducedBy" SG_ 257 Torque_Request_Command_pct "Swc_Pedal";
BA_ "Satisfies" SG_ 257 Torque_Request_Command_pct "SSR-CVC-001";
BA_ "GenSigStartValue" SG_ 257 Torque_Request_Command_pct 0;
BA_ "Timeout_ms" SG_ 257 Torque_Request_Command_pct 30;
BA_ "Owner" SG_ 258 Steer_Command_SteerAngleCmd "Swc_VehicleState";
BA_ "ProducedBy" SG_ 258 Steer_Command_SteerAngleCmd "Swc_CvcCom";
BA_ "Satisfies" SG_ 258 Steer_Command_SteerAngleCmd "SSR-CVC-002";
BA_ "GenSigStartValue" SG_ 258 Steer_Command_SteerAngleCmd 0;
BA_ "Timeout_ms" SG_ 258 Steer_Command_SteerAngleCmd 30;
BA_ "Owner" SG_ 259 Brake_Command_BrakeForceCmd "Swc_VehicleState";
BA_ "ProducedBy" SG_ 259 Brake_Command_BrakeForceCmd "Swc_CvcCom";
BA_ "Satisfies" SG_ 259 Brake_Command_BrakeForceCmd "SSR-CVC-003";
BA_ "GenSigStartValue" SG_ 259 Brake_Command_BrakeForceCmd 0;
BA_ "Timeout_ms" SG_ 259 Brake_Command_BrakeForceCmd 30;
BA_ "Owner" SG_ 768 Motor_Status_MotorFaultStatus "Swc_Motor";
BA_ "ProducedBy" SG_ 768 Motor_Status_MotorFaultStatus "Swc_Motor";
BA_ "Satisfies" SG_ 768 Motor_Status_MotorFaultStatus "SSR-RZC-001 SSR-RZC-003";
BA_ "GenSigStartValue" SG_ 768 Motor_Status_MotorFaultStatus 0;
BA_ "Timeout_ms" SG_ 768 Motor_Status_MotorFaultStatus 60;
BA_ "Owner" SG_ 768 Motor_Status_MotorSpeed_RPM "Swc_Encoder";
BA_ "ProducedBy" SG_ 768 Motor_Status_MotorSpeed_RPM "Swc_RzcCom";
BA_ "GenSigStartValue" SG_ 768 Motor_Status_MotorSpeed_RPM 0;
BA_ "Owner" SG_ 769 Motor_Current_Phase_mA "Swc_CurrentMonitor";
BA_ "ProducedBy" SG_ 769 Motor_Current_Phase_mA "Swc_RzcCom";
BA_ "Satisfies" SG_ 769 Motor_Current_Phase_mA "SSR-RZC-002";
BA_ "GenSigStartValue" SG_ 769 Motor_Current_Phase_mA 0;
BA_ "Owner" SG_ 769 Motor_Current_OvercurrentFlag "Swc_CurrentMonitor";
BA_ "ProducedBy" SG_ 769 Motor_Current_OvercurrentFlag "Swc_RzcCom";
BA_ "Satisfies" SG_ 769 Motor_Current_OvercurrentFlag "SSR-RZC-002";
BA_ "GenSigStartValue" SG_ 769 Motor_Current_OvercurrentFlag 0;
BA_ "Timeout_ms" SG_ 769 Motor_Current_OvercurrentFlag 30;
BA_ "Owner" SG_ 770 Motor_Temperature_WindingTemp1_C "Swc_TempMonitor";
BA_ "ProducedBy" SG_ 770 Motor_Temperature_WindingTemp1_C "Swc_RzcCom";
BA_ "Satisfies" SG_ 770 Motor_Temperature_WindingTemp1_C "SSR-RZC-003";
BA_ "GenSigStartValue" SG_ 770 Motor_Temperature_WindingTemp1_C 250;
BA_ "Owner" SG_ 771 Battery_Status_BatteryVoltage_mV "Swc_Battery";
BA_ "ProducedBy" SG_ 771 Battery_Status_BatteryVoltage_mV "Swc_RzcCom";
BA_ "Satisfies" SG_ 771 Battery_Status_BatteryVoltage_mV "SSR-RZC-006";
BA_ "GenSigStartValue" SG_ 771 Battery_Status_BatteryVoltage_mV 12600;
BA_ "Owner" SG_ 771 Battery_Status_Level "Swc_Battery";
BA_ "ProducedBy" SG_ 771 Battery_Status_Level "Swc_RzcCom";
BA_ "GenSigStartValue" SG_ 771 Battery_Status_Level 2;
BA_ "Owner" SG_ 1 EStop_Broadcast_Active "Swc_EStop";
BA_ "ProducedBy" SG_ 1 EStop_Broadcast_Active "Swc_EStop";
BA_ "Satisfies" SG_ 1 EStop_Broadcast_Active "TSR-046 SSR-CVC-018";
BA_ "GenSigStartValue" SG_ 1 EStop_Broadcast_Active 0;
BA_ "Timeout_ms" SG_ 1 EStop_Broadcast_Active 30;
BA_ "Owner" SG_ 19 SC_Status_RelayEnergized "SC firmware (sc_relay.c)";
BA_ "ProducedBy" SG_ 19 SC_Status_RelayEnergized "SC CAN TX";
BA_ "Satisfies" SG_ 19 SC_Status_RelayEnergized "TSR-040 SSR-SC-001";
BA_ "GenSigStartValue" SG_ 19 SC_Status_RelayEnergized 1;
BA_ "Timeout_ms" SG_ 19 SC_Status_RelayEnergized 1500;
BA_ "Owner" SG_ 528 Brake_Fault_FaultType "Swc_Brake";
BA_ "ProducedBy" SG_ 528 Brake_Fault_FaultType "Swc_FzcCom";
BA_ "Satisfies" SG_ 528 Brake_Fault_FaultType "SSR-FZC-005";
BA_ "GenSigStartValue" SG_ 528 Brake_Fault_FaultType 0;
BA_ "Owner" SG_ 529 Motor_Cutoff_Req_RequestType "Swc_FzcSafety";
BA_ "ProducedBy" SG_ 529 Motor_Cutoff_Req_RequestType "Swc_FzcCom";
BA_ "Satisfies" SG_ 529 Motor_Cutoff_Req_RequestType "SSR-FZC-006";
BA_ "GenSigStartValue" SG_ 529 Motor_Cutoff_Req_RequestType 0;
BA_ "Timeout_ms" SG_ 529 Motor_Cutoff_Req_RequestType 30;
BA_ "Owner" SG_ 1280 DTC_Broadcast_Number "BSW Dem module";
BA_ "ProducedBy" SG_ 1280 DTC_Broadcast_Number "Dem_MainFunction";
BA_ "GenSigStartValue" SG_ 1280 DTC_Broadcast_Number 0;
BA_ "Owner" SG_ 1 EStop_Broadcast_E2E_DataID "Swc_CvcCom";
BA_ "ProducedBy" SG_ 1 EStop_Broadcast_E2E_DataID "Swc_CvcCom";
BA_ "GenSigStartValue" SG_ 1 EStop_Broadcast_E2E_DataID 0;
BA_ "Owner" SG_ 1 EStop_Broadcast_E2E_AliveCounter "Swc_CvcCom";
BA_ "ProducedBy" SG_ 1 EStop_Broadcast_E2E_AliveCounter "Swc_CvcCom";
BA_ "GenSigStartValue" SG_ 1 EStop_Broadcast_E2E_AliveCounter 0;
BA_ "Owner" SG_ 1 EStop_Broadcast_E2E_CRC8 "Swc_CvcCom";
BA_ "ProducedBy" SG_ 1 EStop_Broadcast_E2E_CRC8 "Swc_CvcCom";
BA_ "GenSigStartValue" SG_ 1 EStop_Broadcast_E2E_CRC8 0;
BA_ "Owner" SG_ 1 EStop_Broadcast_Source "Swc_CvcCom";
BA_ "ProducedBy" SG_ 1 EStop_Broadcast_Source "Swc_CvcCom";
BA_ "GenSigStartValue" SG_ 1 EStop_Broadcast_Source 0;
BA_ "Owner" SG_ 16 CVC_Heartbeat_E2E_DataID "Swc_CvcCom";
BA_ "ProducedBy" SG_ 16 CVC_Heartbeat_E2E_DataID "Swc_CvcCom";
BA_ "GenSigStartValue" SG_ 16 CVC_Heartbeat_E2E_DataID 0;
BA_ "Owner" SG_ 16 CVC_Heartbeat_E2E_AliveCounter "Swc_CvcCom";
BA_ "ProducedBy" SG_ 16 CVC_Heartbeat_E2E_AliveCounter "Swc_CvcCom";
BA_ "GenSigStartValue" SG_ 16 CVC_Heartbeat_E2E_AliveCounter 0;
BA_ "Owner" SG_ 16 CVC_Heartbeat_E2E_CRC8 "Swc_CvcCom";
BA_ "ProducedBy" SG_ 16 CVC_Heartbeat_E2E_CRC8 "Swc_CvcCom";
BA_ "GenSigStartValue" SG_ 16 CVC_Heartbeat_E2E_CRC8 0;
BA_ "Owner" SG_ 16 CVC_Heartbeat_ECU_ID "Swc_Heartbeat";
BA_ "ProducedBy" SG_ 16 CVC_Heartbeat_ECU_ID "Swc_CvcCom";
BA_ "GenSigStartValue" SG_ 16 CVC_Heartbeat_ECU_ID 0;
BA_ "Owner" SG_ 16 CVC_Heartbeat_OperatingMode "Swc_Heartbeat";
BA_ "ProducedBy" SG_ 16 CVC_Heartbeat_OperatingMode "Swc_CvcCom";
BA_ "GenSigStartValue" SG_ 16 CVC_Heartbeat_OperatingMode 0;
BA_ "Owner" SG_ 16 CVC_Heartbeat_FaultStatus "Swc_Heartbeat";
BA_ "ProducedBy" SG_ 16 CVC_Heartbeat_FaultStatus "Swc_CvcCom";
BA_ "GenSigStartValue" SG_ 16 CVC_Heartbeat_FaultStatus 0;
BA_ "Owner" SG_ 17 FZC_Heartbeat_E2E_DataID "Swc_FzcCom";
BA_ "ProducedBy" SG_ 17 FZC_Heartbeat_E2E_DataID "Swc_FzcCom";
BA_ "GenSigStartValue" SG_ 17 FZC_Heartbeat_E2E_DataID 0;
BA_ "Owner" SG_ 17 FZC_Heartbeat_E2E_AliveCounter "Swc_FzcCom";
BA_ "ProducedBy" SG_ 17 FZC_Heartbeat_E2E_AliveCounter "Swc_FzcCom";
BA_ "GenSigStartValue" SG_ 17 FZC_Heartbeat_E2E_AliveCounter 0;
BA_ "Owner" SG_ 17 FZC_Heartbeat_E2E_CRC8 "Swc_FzcCom";
BA_ "ProducedBy" SG_ 17 FZC_Heartbeat_E2E_CRC8 "Swc_FzcCom";
BA_ "GenSigStartValue" SG_ 17 FZC_Heartbeat_E2E_CRC8 0;
BA_ "Owner" SG_ 17 FZC_Heartbeat_ECU_ID "Swc_Heartbeat";
BA_ "ProducedBy" SG_ 17 FZC_Heartbeat_ECU_ID "Swc_FzcCom";
BA_ "GenSigStartValue" SG_ 17 FZC_Heartbeat_ECU_ID 0;
BA_ "Owner" SG_ 17 FZC_Heartbeat_OperatingMode "Swc_Heartbeat";
BA_ "ProducedBy" SG_ 17 FZC_Heartbeat_OperatingMode "Swc_FzcCom";
BA_ "GenSigStartValue" SG_ 17 FZC_Heartbeat_OperatingMode 0;
BA_ "Owner" SG_ 17 FZC_Heartbeat_FaultStatus "Swc_Heartbeat";
BA_ "ProducedBy" SG_ 17 FZC_Heartbeat_FaultStatus "Swc_FzcCom";
BA_ "GenSigStartValue" SG_ 17 FZC_Heartbeat_FaultStatus 0;
BA_ "Owner" SG_ 18 RZC_Heartbeat_E2E_DataID "Swc_RzcCom";
BA_ "ProducedBy" SG_ 18 RZC_Heartbeat_E2E_DataID "Swc_RzcCom";
BA_ "GenSigStartValue" SG_ 18 RZC_Heartbeat_E2E_DataID 0;
BA_ "Owner" SG_ 18 RZC_Heartbeat_E2E_AliveCounter "Swc_RzcCom";
BA_ "ProducedBy" SG_ 18 RZC_Heartbeat_E2E_AliveCounter "Swc_RzcCom";
BA_ "GenSigStartValue" SG_ 18 RZC_Heartbeat_E2E_AliveCounter 0;
BA_ "Owner" SG_ 18 RZC_Heartbeat_E2E_CRC8 "Swc_RzcCom";
BA_ "ProducedBy" SG_ 18 RZC_Heartbeat_E2E_CRC8 "Swc_RzcCom";
BA_ "GenSigStartValue" SG_ 18 RZC_Heartbeat_E2E_CRC8 0;
BA_ "Owner" SG_ 18 RZC_Heartbeat_ECU_ID "Swc_Heartbeat";
BA_ "ProducedBy" SG_ 18 RZC_Heartbeat_ECU_ID "Swc_RzcCom";
BA_ "GenSigStartValue" SG_ 18 RZC_Heartbeat_ECU_ID 0;
BA_ "Owner" SG_ 18 RZC_Heartbeat_OperatingMode "Swc_Heartbeat";
BA_ "ProducedBy" SG_ 18 RZC_Heartbeat_OperatingMode "Swc_RzcCom";
BA_ "GenSigStartValue" SG_ 18 RZC_Heartbeat_OperatingMode 0;
BA_ "Owner" SG_ 18 RZC_Heartbeat_FaultStatus "Swc_Heartbeat";
BA_ "ProducedBy" SG_ 18 RZC_Heartbeat_FaultStatus "Swc_RzcCom";
BA_ "GenSigStartValue" SG_ 18 RZC_Heartbeat_FaultStatus 0;
BA_ "Owner" SG_ 19 SC_Status_AliveCounter "SC firmware (sc_monitoring.c)";
BA_ "ProducedBy" SG_ 19 SC_Status_AliveCounter "SC firmware (sc_can.c)";
BA_ "GenSigStartValue" SG_ 19 SC_Status_AliveCounter 0;
BA_ "Owner" SG_ 19 SC_Status_CRC8 "SC firmware (sc_monitoring.c)";
BA_ "ProducedBy" SG_ 19 SC_Status_CRC8 "SC firmware (sc_can.c)";
BA_ "GenSigStartValue" SG_ 19 SC_Status_CRC8 0;
BA_ "Owner" SG_ 19 SC_Status_Mode "SC firmware (sc_state.c)";
BA_ "ProducedBy" SG_ 19 SC_Status_Mode "SC firmware (sc_can.c)";
BA_ "GenSigStartValue" SG_ 19 SC_Status_Mode 0;
BA_ "Owner" SG_ 19 SC_Status_FaultFlags "SC firmware (sc_relay.c)";
BA_ "ProducedBy" SG_ 19 SC_Status_FaultFlags "SC firmware (sc_can.c)";
BA_ "GenSigStartValue" SG_ 19 SC_Status_FaultFlags 0;
BA_ "Owner" SG_ 19 SC_Status_ECU_Health "SC firmware (sc_selftest.c)";
BA_ "ProducedBy" SG_ 19 SC_Status_ECU_Health "SC firmware (sc_can.c)";
BA_ "GenSigStartValue" SG_ 19 SC_Status_ECU_Health 0;
BA_ "Owner" SG_ 19 SC_Status_FaultReason "SC firmware (sc_relay.c)";
BA_ "ProducedBy" SG_ 19 SC_Status_FaultReason "SC firmware (sc_can.c)";
BA_ "GenSigStartValue" SG_ 19 SC_Status_FaultReason 0;
BA_ "Owner" SG_ 20 ICU_Heartbeat_E2E_DataID "Swc_Dashboard";
BA_ "ProducedBy" SG_ 20 ICU_Heartbeat_E2E_DataID "Swc_Dashboard";
BA_ "GenSigStartValue" SG_ 20 ICU_Heartbeat_E2E_DataID 0;
BA_ "Owner" SG_ 20 ICU_Heartbeat_E2E_AliveCounter "Swc_Dashboard";
BA_ "ProducedBy" SG_ 20 ICU_Heartbeat_E2E_AliveCounter "Swc_Dashboard";
BA_ "GenSigStartValue" SG_ 20 ICU_Heartbeat_E2E_AliveCounter 0;
BA_ "Owner" SG_ 20 ICU_Heartbeat_E2E_CRC8 "Swc_Dashboard";
BA_ "ProducedBy" SG_ 20 ICU_Heartbeat_E2E_CRC8 "Swc_Dashboard";
BA_ "GenSigStartValue" SG_ 20 ICU_Heartbeat_E2E_CRC8 0;
BA_ "Owner" SG_ 20 ICU_Heartbeat_AliveCounter "Swc_Dashboard";
BA_ "ProducedBy" SG_ 20 ICU_Heartbeat_AliveCounter "Swc_Dashboard";
BA_ "GenSigStartValue" SG_ 20 ICU_Heartbeat_AliveCounter 0;
BA_ "Owner" SG_ 20 ICU_Heartbeat_ECU_ID "Swc_Dashboard";
BA_ "ProducedBy" SG_ 20 ICU_Heartbeat_ECU_ID "Swc_Dashboard";
BA_ "GenSigStartValue" SG_ 20 ICU_Heartbeat_ECU_ID 0;
BA_ "Owner" SG_ 21 TCU_Heartbeat_E2E_DataID "Swc_UdsServer";
BA_ "ProducedBy" SG_ 21 TCU_Heartbeat_E2E_DataID "Swc_UdsServer";
BA_ "GenSigStartValue" SG_ 21 TCU_Heartbeat_E2E_DataID 0;
BA_ "Owner" SG_ 21 TCU_Heartbeat_E2E_AliveCounter "Swc_UdsServer";
BA_ "ProducedBy" SG_ 21 TCU_Heartbeat_E2E_AliveCounter "Swc_UdsServer";
BA_ "GenSigStartValue" SG_ 21 TCU_Heartbeat_E2E_AliveCounter 0;
BA_ "Owner" SG_ 21 TCU_Heartbeat_E2E_CRC8 "Swc_UdsServer";
BA_ "ProducedBy" SG_ 21 TCU_Heartbeat_E2E_CRC8 "Swc_UdsServer";
BA_ "GenSigStartValue" SG_ 21 TCU_Heartbeat_E2E_CRC8 0;
BA_ "Owner" SG_ 21 TCU_Heartbeat_AliveCounter "Swc_DataAggregator";
BA_ "ProducedBy" SG_ 21 TCU_Heartbeat_AliveCounter "Swc_UdsServer";
BA_ "GenSigStartValue" SG_ 21 TCU_Heartbeat_AliveCounter 0;
BA_ "Owner" SG_ 21 TCU_Heartbeat_ECU_ID "Swc_DataAggregator";
BA_ "ProducedBy" SG_ 21 TCU_Heartbeat_ECU_ID "Swc_UdsServer";
BA_ "GenSigStartValue" SG_ 21 TCU_Heartbeat_ECU_ID 0;
BA_ "Owner" SG_ 22 BCM_Heartbeat_E2E_DataID "Swc_BcmCan";
BA_ "ProducedBy" SG_ 22 BCM_Heartbeat_E2E_DataID "Swc_BcmCan";
BA_ "GenSigStartValue" SG_ 22 BCM_Heartbeat_E2E_DataID 0;
BA_ "Owner" SG_ 22 BCM_Heartbeat_E2E_AliveCounter "Swc_BcmCan";
BA_ "ProducedBy" SG_ 22 BCM_Heartbeat_E2E_AliveCounter "Swc_BcmCan";
BA_ "GenSigStartValue" SG_ 22 BCM_Heartbeat_E2E_AliveCounter 0;
BA_ "Owner" SG_ 22 BCM_Heartbeat_E2E_CRC8 "Swc_BcmCan";
BA_ "ProducedBy" SG_ 22 BCM_Heartbeat_E2E_CRC8 "Swc_BcmCan";
BA_ "GenSigStartValue" SG_ 22 BCM_Heartbeat_E2E_CRC8 0;
BA_ "Owner" SG_ 22 BCM_Heartbeat_AliveCounter "Swc_BcmMain";
BA_ "ProducedBy" SG_ 22 BCM_Heartbeat_AliveCounter "Swc_BcmCan";
BA_ "GenSigStartValue" SG_ 22 BCM_Heartbeat_AliveCounter 0;
BA_ "Owner" SG_ 22 BCM_Heartbeat_ECU_ID "Swc_BcmMain";
BA_ "ProducedBy" SG_ 22 BCM_Heartbeat_ECU_ID "Swc_BcmCan";
BA_ "GenSigStartValue" SG_ 22 BCM_Heartbeat_ECU_ID 0;
BA_ "Owner" SG_ 256 Vehicle_State_E2E_DataID "Swc_CvcCom";
BA_ "ProducedBy" SG_ 256 Vehicle_State_E2E_DataID "Swc_CvcCom";
BA_ "GenSigStartValue" SG_ 256 Vehicle_State_E2E_DataID 0;
BA_ "Owner" SG_ 256 Vehicle_State_E2E_AliveCounter "Swc_CvcCom";
BA_ "ProducedBy" SG_ 256 Vehicle_State_E2E_AliveCounter "Swc_CvcCom";
BA_ "GenSigStartValue" SG_ 256 Vehicle_State_E2E_AliveCounter 0;
BA_ "Owner" SG_ 256 Vehicle_State_E2E_CRC8 "Swc_CvcCom";
BA_ "ProducedBy" SG_ 256 Vehicle_State_E2E_CRC8 "Swc_CvcCom";
BA_ "GenSigStartValue" SG_ 256 Vehicle_State_E2E_CRC8 0;
BA_ "Owner" SG_ 256 Vehicle_State_TorqueLimit "Swc_VehicleState";
BA_ "ProducedBy" SG_ 256 Vehicle_State_TorqueLimit "Swc_CvcCom";
BA_ "GenSigStartValue" SG_ 256 Vehicle_State_TorqueLimit 0;
BA_ "Owner" SG_ 256 Vehicle_State_SpeedLimit "Swc_VehicleState";
BA_ "ProducedBy" SG_ 256 Vehicle_State_SpeedLimit "Swc_CvcCom";
BA_ "GenSigStartValue" SG_ 256 Vehicle_State_SpeedLimit 0;
BA_ "Owner" SG_ 257 Torque_Request_E2E_DataID "Swc_CvcCom";
BA_ "ProducedBy" SG_ 257 Torque_Request_E2E_DataID "Swc_CvcCom";
BA_ "GenSigStartValue" SG_ 257 Torque_Request_E2E_DataID 0;
BA_ "Owner" SG_ 257 Torque_Request_E2E_AliveCounter "Swc_CvcCom";
BA_ "ProducedBy" SG_ 257 Torque_Request_E2E_AliveCounter "Swc_CvcCom";
BA_ "GenSigStartValue" SG_ 257 Torque_Request_E2E_AliveCounter 0;
BA_ "Owner" SG_ 257 Torque_Request_E2E_CRC8 "Swc_CvcCom";
BA_ "ProducedBy" SG_ 257 Torque_Request_E2E_CRC8 "Swc_CvcCom";
BA_ "GenSigStartValue" SG_ 257 Torque_Request_E2E_CRC8 0;
BA_ "Owner" SG_ 257 Torque_Request_Direction "Swc_Pedal";
BA_ "ProducedBy" SG_ 257 Torque_Request_Direction "Swc_CvcCom";
BA_ "GenSigStartValue" SG_ 257 Torque_Request_Direction 0;
BA_ "Owner" SG_ 257 Torque_Request_PedalPosition1 "Swc_Pedal";
BA_ "ProducedBy" SG_ 257 Torque_Request_PedalPosition1 "Swc_CvcCom";
BA_ "GenSigStartValue" SG_ 257 Torque_Request_PedalPosition1 0;
BA_ "Owner" SG_ 257 Torque_Request_PedalPosition2 "Swc_Pedal";
BA_ "ProducedBy" SG_ 257 Torque_Request_PedalPosition2 "Swc_CvcCom";
BA_ "GenSigStartValue" SG_ 257 Torque_Request_PedalPosition2 0;
BA_ "Owner" SG_ 257 Torque_Request_PedalFault "Swc_Pedal";
BA_ "ProducedBy" SG_ 257 Torque_Request_PedalFault "Swc_CvcCom";
BA_ "GenSigStartValue" SG_ 257 Torque_Request_PedalFault 0;
BA_ "Owner" SG_ 258 Steer_Command_E2E_DataID "Swc_CvcCom";
BA_ "ProducedBy" SG_ 258 Steer_Command_E2E_DataID "Swc_CvcCom";
BA_ "GenSigStartValue" SG_ 258 Steer_Command_E2E_DataID 0;
BA_ "Owner" SG_ 258 Steer_Command_E2E_AliveCounter "Swc_CvcCom";
BA_ "ProducedBy" SG_ 258 Steer_Command_E2E_AliveCounter "Swc_CvcCom";
BA_ "GenSigStartValue" SG_ 258 Steer_Command_E2E_AliveCounter 0;
BA_ "Owner" SG_ 258 Steer_Command_E2E_CRC8 "Swc_CvcCom";
BA_ "ProducedBy" SG_ 258 Steer_Command_E2E_CRC8 "Swc_CvcCom";
BA_ "GenSigStartValue" SG_ 258 Steer_Command_E2E_CRC8 0;
BA_ "Owner" SG_ 258 Steer_Command_SteerRateLimit "Swc_CvcCom";
BA_ "ProducedBy" SG_ 258 Steer_Command_SteerRateLimit "Swc_CvcCom";
BA_ "GenSigStartValue" SG_ 258 Steer_Command_SteerRateLimit 0;
BA_ "Owner" SG_ 258 Steer_Command_VehicleState "Swc_VehicleState";
BA_ "ProducedBy" SG_ 258 Steer_Command_VehicleState "Swc_CvcCom";
BA_ "GenSigStartValue" SG_ 258 Steer_Command_VehicleState 0;
BA_ "Owner" SG_ 259 Brake_Command_E2E_DataID "Swc_CvcCom";
BA_ "ProducedBy" SG_ 259 Brake_Command_E2E_DataID "Swc_CvcCom";
BA_ "GenSigStartValue" SG_ 259 Brake_Command_E2E_DataID 0;
BA_ "Owner" SG_ 259 Brake_Command_E2E_AliveCounter "Swc_CvcCom";
BA_ "ProducedBy" SG_ 259 Brake_Command_E2E_AliveCounter "Swc_CvcCom";
BA_ "GenSigStartValue" SG_ 259 Brake_Command_E2E_AliveCounter 0;
BA_ "Owner" SG_ 259 Brake_Command_E2E_CRC8 "Swc_CvcCom";
BA_ "ProducedBy" SG_ 259 Brake_Command_E2E_CRC8 "Swc_CvcCom";
BA_ "GenSigStartValue" SG_ 259 Brake_Command_E2E_CRC8 0;
BA_ "Owner" SG_ 259 Brake_Command_BrakeMode "Swc_CvcCom";
BA_ "ProducedBy" SG_ 259 Brake_Command_BrakeMode "Swc_CvcCom";
BA_ "GenSigStartValue" SG_ 259 Brake_Command_BrakeMode 0;
BA_ "Owner" SG_ 259 Brake_Command_VehicleState "Swc_VehicleState";
BA_ "ProducedBy" SG_ 259 Brake_Command_VehicleState "Swc_CvcCom";
BA_ "GenSigStartValue" SG_ 259 Brake_Command_VehicleState 0;
BA_ "Owner" SG_ 512 Steering_Status_E2E_DataID "Swc_FzcCom";
BA_ "ProducedBy" SG_ 512 Steering_Status_E2E_DataID "Swc_FzcCom";
BA_ "GenSigStartValue" SG_ 512 Steering_Status_E2E_DataID 0;
BA_ "Owner" SG_ 512 Steering_Status_E2E_AliveCounter "Swc_FzcCom";
BA_ "ProducedBy" SG_ 512 Steering_Status_E2E_AliveCounter "Swc_FzcCom";
BA_ "GenSigStartValue" SG_ 512 Steering_Status_E2E_AliveCounter 0;
BA_ "Owner" SG_ 512 Steering_Status_E2E_CRC8 "Swc_FzcCom";
BA_ "ProducedBy" SG_ 512 Steering_Status_E2E_CRC8 "Swc_FzcCom";
BA_ "GenSigStartValue" SG_ 512 Steering_Status_E2E_CRC8 0;
BA_ "Owner" SG_ 512 Steering_Status_ActualAngle "Swc_Steering";
BA_ "ProducedBy" SG_ 512 Steering_Status_ActualAngle "Swc_FzcCom";
BA_ "GenSigStartValue" SG_ 512 Steering_Status_ActualAngle 0;
BA_ "Owner" SG_ 512 Steering_Status_CommandedAngle "Swc_Steering";
BA_ "ProducedBy" SG_ 512 Steering_Status_CommandedAngle "Swc_FzcCom";
BA_ "GenSigStartValue" SG_ 512 Steering_Status_CommandedAngle 0;
BA_ "Owner" SG_ 512 Steering_Status_SteerFaultStatus "Swc_Steering";
BA_ "ProducedBy" SG_ 512 Steering_Status_SteerFaultStatus "Swc_FzcCom";
BA_ "GenSigStartValue" SG_ 512 Steering_Status_SteerFaultStatus 0;
BA_ "Owner" SG_ 512 Steering_Status_SteerMode "Swc_Steering";
BA_ "ProducedBy" SG_ 512 Steering_Status_SteerMode "Swc_FzcCom";
BA_ "GenSigStartValue" SG_ 512 Steering_Status_SteerMode 0;
BA_ "Owner" SG_ 512 Steering_Status_ServoCurrent_mA "Swc_Steering";
BA_ "ProducedBy" SG_ 512 Steering_Status_ServoCurrent_mA "Swc_FzcCom";
BA_ "GenSigStartValue" SG_ 512 Steering_Status_ServoCurrent_mA 0;
BA_ "Owner" SG_ 513 Brake_Status_E2E_DataID "Swc_FzcCom";
BA_ "ProducedBy" SG_ 513 Brake_Status_E2E_DataID "Swc_FzcCom";
BA_ "GenSigStartValue" SG_ 513 Brake_Status_E2E_DataID 0;
BA_ "Owner" SG_ 513 Brake_Status_E2E_AliveCounter "Swc_FzcCom";
BA_ "ProducedBy" SG_ 513 Brake_Status_E2E_AliveCounter "Swc_FzcCom";
BA_ "GenSigStartValue" SG_ 513 Brake_Status_E2E_AliveCounter 0;
BA_ "Owner" SG_ 513 Brake_Status_E2E_CRC8 "Swc_FzcCom";
BA_ "ProducedBy" SG_ 513 Brake_Status_E2E_CRC8 "Swc_FzcCom";
BA_ "GenSigStartValue" SG_ 513 Brake_Status_E2E_CRC8 0;
BA_ "Owner" SG_ 513 Brake_Status_BrakePosition "Swc_Brake";
BA_ "ProducedBy" SG_ 513 Brake_Status_BrakePosition "Swc_FzcCom";
BA_ "GenSigStartValue" SG_ 513 Brake_Status_BrakePosition 0;
BA_ "Owner" SG_ 513 Brake_Status_BrakeCommandEcho "Swc_Brake";
BA_ "ProducedBy" SG_ 513 Brake_Status_BrakeCommandEcho "Swc_FzcCom";
BA_ "GenSigStartValue" SG_ 513 Brake_Status_BrakeCommandEcho 0;
BA_ "Owner" SG_ 513 Brake_Status_ServoCurrent_mA "Swc_Brake";
BA_ "ProducedBy" SG_ 513 Brake_Status_ServoCurrent_mA "Swc_FzcCom";
BA_ "GenSigStartValue" SG_ 513 Brake_Status_ServoCurrent_mA 0;
BA_ "Owner" SG_ 513 Brake_Status_BrakeFaultStatus "Swc_Brake";
BA_ "ProducedBy" SG_ 513 Brake_Status_BrakeFaultStatus "Swc_FzcCom";
BA_ "GenSigStartValue" SG_ 513 Brake_Status_BrakeFaultStatus 0;
BA_ "Owner" SG_ 513 Brake_Status_BrakeMode "Swc_Brake";
BA_ "ProducedBy" SG_ 513 Brake_Status_BrakeMode "Swc_FzcCom";
BA_ "GenSigStartValue" SG_ 513 Brake_Status_BrakeMode 0;
BA_ "Owner" SG_ 528 Brake_Fault_E2E_DataID "Swc_FzcCom";
BA_ "ProducedBy" SG_ 528 Brake_Fault_E2E_DataID "Swc_FzcCom";
BA_ "GenSigStartValue" SG_ 528 Brake_Fault_E2E_DataID 0;
BA_ "Owner" SG_ 528 Brake_Fault_E2E_AliveCounter "Swc_FzcCom";
BA_ "ProducedBy" SG_ 528 Brake_Fault_E2E_AliveCounter "Swc_FzcCom";
BA_ "GenSigStartValue" SG_ 528 Brake_Fault_E2E_AliveCounter 0;
BA_ "Owner" SG_ 528 Brake_Fault_E2E_CRC8 "Swc_FzcCom";
BA_ "ProducedBy" SG_ 528 Brake_Fault_E2E_CRC8 "Swc_FzcCom";
BA_ "GenSigStartValue" SG_ 528 Brake_Fault_E2E_CRC8 0;
BA_ "Owner" SG_ 528 Brake_Fault_CommandedBrake "Swc_Brake";
BA_ "ProducedBy" SG_ 528 Brake_Fault_CommandedBrake "Swc_FzcCom";
BA_ "GenSigStartValue" SG_ 528 Brake_Fault_CommandedBrake 0;
BA_ "Owner" SG_ 528 Brake_Fault_MeasuredBrake "Swc_Brake";
BA_ "ProducedBy" SG_ 528 Brake_Fault_MeasuredBrake "Swc_FzcCom";
BA_ "GenSigStartValue" SG_ 528 Brake_Fault_MeasuredBrake 0;
BA_ "Owner" SG_ 529 Motor_Cutoff_Req_E2E_DataID "Swc_FzcCom";
BA_ "ProducedBy" SG_ 529 Motor_Cutoff_Req_E2E_DataID "Swc_FzcCom";
BA_ "GenSigStartValue" SG_ 529 Motor_Cutoff_Req_E2E_DataID 0;
BA_ "Owner" SG_ 529 Motor_Cutoff_Req_E2E_AliveCounter "Swc_FzcCom";
BA_ "ProducedBy" SG_ 529 Motor_Cutoff_Req_E2E_AliveCounter "Swc_FzcCom";
BA_ "GenSigStartValue" SG_ 529 Motor_Cutoff_Req_E2E_AliveCounter 0;
BA_ "Owner" SG_ 529 Motor_Cutoff_Req_E2E_CRC8 "Swc_FzcCom";
BA_ "ProducedBy" SG_ 529 Motor_Cutoff_Req_E2E_CRC8 "Swc_FzcCom";
BA_ "GenSigStartValue" SG_ 529 Motor_Cutoff_Req_E2E_CRC8 0;
BA_ "Owner" SG_ 529 Motor_Cutoff_Req_Reason "Swc_FzcSafety";
BA_ "ProducedBy" SG_ 529 Motor_Cutoff_Req_Reason "Swc_FzcCom";
BA_ "GenSigStartValue" SG_ 529 Motor_Cutoff_Req_Reason 0;
BA_ "Owner" SG_ 544 Lidar_Distance_E2E_DataID "Swc_FzcCom";
BA_ "ProducedBy" SG_ 544 Lidar_Distance_E2E_DataID "Swc_FzcCom";
BA_ "GenSigStartValue" SG_ 544 Lidar_Distance_E2E_DataID 0;
BA_ "Owner" SG_ 544 Lidar_Distance_E2E_AliveCounter "Swc_FzcCom";
BA_ "ProducedBy" SG_ 544 Lidar_Distance_E2E_AliveCounter "Swc_FzcCom";
BA_ "GenSigStartValue" SG_ 544 Lidar_Distance_E2E_AliveCounter 0;
BA_ "Owner" SG_ 544 Lidar_Distance_E2E_CRC8 "Swc_FzcCom";
BA_ "ProducedBy" SG_ 544 Lidar_Distance_E2E_CRC8 "Swc_FzcCom";
BA_ "GenSigStartValue" SG_ 544 Lidar_Distance_E2E_CRC8 0;
BA_ "Owner" SG_ 544 Lidar_Distance_Range_cm "Swc_Lidar";
BA_ "ProducedBy" SG_ 544 Lidar_Distance_Range_cm "Swc_FzcCom";
BA_ "GenSigStartValue" SG_ 544 Lidar_Distance_Range_cm 0;
BA_ "Owner" SG_ 544 Lidar_Distance_SignalStrength "Swc_Lidar";
BA_ "ProducedBy" SG_ 544 Lidar_Distance_SignalStrength "Swc_FzcCom";
BA_ "GenSigStartValue" SG_ 544 Lidar_Distance_SignalStrength 0;
BA_ "Owner" SG_ 544 Lidar_Distance_ObstacleZone "Swc_Lidar";
BA_ "ProducedBy" SG_ 544 Lidar_Distance_ObstacleZone "Swc_FzcCom";
BA_ "GenSigStartValue" SG_ 544 Lidar_Distance_ObstacleZone 0;
BA_ "Owner" SG_ 544 Lidar_Distance_SensorStatus "Swc_Lidar";
BA_ "ProducedBy" SG_ 544 Lidar_Distance_SensorStatus "Swc_FzcCom";
BA_ "GenSigStartValue" SG_ 544 Lidar_Distance_SensorStatus 0;
BA_ "Owner" SG_ 768 Motor_Status_E2E_DataID "Swc_RzcCom";
BA_ "ProducedBy" SG_ 768 Motor_Status_E2E_DataID "Swc_RzcCom";
BA_ "GenSigStartValue" SG_ 768 Motor_Status_E2E_DataID 0;
BA_ "Owner" SG_ 768 Motor_Status_E2E_AliveCounter "Swc_RzcCom";
BA_ "ProducedBy" SG_ 768 Motor_Status_E2E_AliveCounter "Swc_RzcCom";
BA_ "GenSigStartValue" SG_ 768 Motor_Status_E2E_AliveCounter 0;
BA_ "Owner" SG_ 768 Motor_Status_E2E_CRC8 "Swc_RzcCom";
BA_ "ProducedBy" SG_ 768 Motor_Status_E2E_CRC8 "Swc_RzcCom";
BA_ "GenSigStartValue" SG_ 768 Motor_Status_E2E_CRC8 0;
BA_ "Owner" SG_ 768 Motor_Status_TorqueEcho "Swc_Motor";
BA_ "ProducedBy" SG_ 768 Motor_Status_TorqueEcho "Swc_RzcCom";
BA_ "GenSigStartValue" SG_ 768 Motor_Status_TorqueEcho 0;
BA_ "Owner" SG_ 768 Motor_Status_MotorDirection "Swc_Motor";
BA_ "ProducedBy" SG_ 768 Motor_Status_MotorDirection "Swc_RzcCom";
BA_ "GenSigStartValue" SG_ 768 Motor_Status_MotorDirection 0;
BA_ "Owner" SG_ 768 Motor_Status_MotorEnable "Swc_Motor";
BA_ "ProducedBy" SG_ 768 Motor_Status_MotorEnable "Swc_RzcCom";
BA_ "GenSigStartValue" SG_ 768 Motor_Status_MotorEnable 0;
BA_ "Owner" SG_ 769 Motor_Current_E2E_DataID "Swc_RzcCom";
BA_ "ProducedBy" SG_ 769 Motor_Current_E2E_DataID "Swc_RzcCom";
BA_ "GenSigStartValue" SG_ 769 Motor_Current_E2E_DataID 0;
BA_ "Owner" SG_ 769 Motor_Current_E2E_AliveCounter "Swc_RzcCom";
BA_ "ProducedBy" SG_ 769 Motor_Current_E2E_AliveCounter "Swc_RzcCom";
BA_ "GenSigStartValue" SG_ 769 Motor_Current_E2E_AliveCounter 0;
BA_ "Owner" SG_ 769 Motor_Current_E2E_CRC8 "Swc_RzcCom";
BA_ "ProducedBy" SG_ 769 Motor_Current_E2E_CRC8 "Swc_RzcCom";
BA_ "GenSigStartValue" SG_ 769 Motor_Current_E2E_CRC8 0;
BA_ "Owner" SG_ 769 Motor_Current_DirIsReverse "Swc_CurrentMonitor";
BA_ "ProducedBy" SG_ 769 Motor_Current_DirIsReverse "Swc_RzcCom";
BA_ "GenSigStartValue" SG_ 769 Motor_Current_DirIsReverse 0;
BA_ "Owner" SG_ 769 Motor_Current_MotorEnable "Swc_Motor";
BA_ "ProducedBy" SG_ 769 Motor_Current_MotorEnable "Swc_RzcCom";
BA_ "GenSigStartValue" SG_ 769 Motor_Current_MotorEnable 0;
BA_ "Owner" SG_ 769 Motor_Current_TorqueEcho "Swc_Motor";
BA_ "ProducedBy" SG_ 769 Motor_Current_TorqueEcho "Swc_RzcCom";
BA_ "GenSigStartValue" SG_ 769 Motor_Current_TorqueEcho 0;
BA_ "Owner" SG_ 770 Motor_Temperature_E2E_DataID "Swc_RzcCom";
BA_ "ProducedBy" SG_ 770 Motor_Temperature_E2E_DataID "Swc_RzcCom";
BA_ "GenSigStartValue" SG_ 770 Motor_Temperature_E2E_DataID 0;
BA_ "Owner" SG_ 770 Motor_Temperature_E2E_AliveCounter "Swc_RzcCom";
BA_ "ProducedBy" SG_ 770 Motor_Temperature_E2E_AliveCounter "Swc_RzcCom";
BA_ "GenSigStartValue" SG_ 770 Motor_Temperature_E2E_AliveCounter 0;
BA_ "Owner" SG_ 770 Motor_Temperature_E2E_CRC8 "Swc_RzcCom";
BA_ "ProducedBy" SG_ 770 Motor_Temperature_E2E_CRC8 "Swc_RzcCom";
BA_ "GenSigStartValue" SG_ 770 Motor_Temperature_E2E_CRC8 0;
BA_ "Owner" SG_ 770 Motor_Temperature_WindingTemp2_C "Swc_TempMonitor";
BA_ "ProducedBy" SG_ 770 Motor_Temperature_WindingTemp2_C "Swc_RzcCom";
BA_ "GenSigStartValue" SG_ 770 Motor_Temperature_WindingTemp2_C 0;
BA_ "Owner" SG_ 770 Motor_Temperature_DeratingPercent "Swc_TempMonitor";
BA_ "ProducedBy" SG_ 770 Motor_Temperature_DeratingPercent "Swc_RzcCom";
BA_ "GenSigStartValue" SG_ 770 Motor_Temperature_DeratingPercent 0;
BA_ "Owner" SG_ 771 Battery_Status_E2E_DataID "Swc_RzcCom";
BA_ "ProducedBy" SG_ 771 Battery_Status_E2E_DataID "Swc_RzcCom";
BA_ "GenSigStartValue" SG_ 771 Battery_Status_E2E_DataID 0;
BA_ "Owner" SG_ 771 Battery_Status_E2E_AliveCounter "Swc_RzcCom";
BA_ "ProducedBy" SG_ 771 Battery_Status_E2E_AliveCounter "Swc_RzcCom";
BA_ "GenSigStartValue" SG_ 771 Battery_Status_E2E_AliveCounter 0;
BA_ "Owner" SG_ 771 Battery_Status_E2E_CRC8 "Swc_RzcCom";
BA_ "ProducedBy" SG_ 771 Battery_Status_E2E_CRC8 "Swc_RzcCom";
BA_ "GenSigStartValue" SG_ 771 Battery_Status_E2E_CRC8 0;
BA_ "Owner" SG_ 848 Body_Control_Cmd_HeadlightCmd "Swc_CvcCom";
BA_ "ProducedBy" SG_ 848 Body_Control_Cmd_HeadlightCmd "Swc_CvcCom";
BA_ "GenSigStartValue" SG_ 848 Body_Control_Cmd_HeadlightCmd 0;
BA_ "Owner" SG_ 848 Body_Control_Cmd_TailLightOn "Swc_CvcCom";
BA_ "ProducedBy" SG_ 848 Body_Control_Cmd_TailLightOn "Swc_CvcCom";
BA_ "GenSigStartValue" SG_ 848 Body_Control_Cmd_TailLightOn 0;
BA_ "Owner" SG_ 848 Body_Control_Cmd_HazardActive "Swc_CvcCom";
BA_ "ProducedBy" SG_ 848 Body_Control_Cmd_HazardActive "Swc_CvcCom";
BA_ "GenSigStartValue" SG_ 848 Body_Control_Cmd_HazardActive 0;
BA_ "Owner" SG_ 848 Body_Control_Cmd_TurnSignalCmd "Swc_CvcCom";
BA_ "ProducedBy" SG_ 848 Body_Control_Cmd_TurnSignalCmd "Swc_CvcCom";
BA_ "GenSigStartValue" SG_ 848 Body_Control_Cmd_TurnSignalCmd 0;
BA_ "Owner" SG_ 848 Body_Control_Cmd_DoorLockCmd "Swc_CvcCom";
BA_ "ProducedBy" SG_ 848 Body_Control_Cmd_DoorLockCmd "Swc_CvcCom";
BA_ "GenSigStartValue" SG_ 848 Body_Control_Cmd_DoorLockCmd 0;
BA_ "Owner" SG_ 1024 Light_Status_HeadlightOn "Swc_Lights";
BA_ "ProducedBy" SG_ 1024 Light_Status_HeadlightOn "Swc_BcmCan";
BA_ "GenSigStartValue" SG_ 1024 Light_Status_HeadlightOn 0;
BA_ "Owner" SG_ 1024 Light_Status_TailLightOn "Swc_Lights";
BA_ "ProducedBy" SG_ 1024 Light_Status_TailLightOn "Swc_BcmCan";
BA_ "GenSigStartValue" SG_ 1024 Light_Status_TailLightOn 0;
BA_ "Owner" SG_ 1024 Light_Status_FogLightOn "Swc_Lights";
BA_ "ProducedBy" SG_ 1024 Light_Status_FogLightOn "Swc_BcmCan";
BA_ "GenSigStartValue" SG_ 1024 Light_Status_FogLightOn 0;
BA_ "Owner" SG_ 1024 Light_Status_BrakeLightOn "Swc_Lights";
BA_ "ProducedBy" SG_ 1024 Light_Status_BrakeLightOn "Swc_BcmCan";
BA_ "GenSigStartValue" SG_ 1024 Light_Status_BrakeLightOn 0;
BA_ "Owner" SG_ 1024 Light_Status_HeadlightLevel "Swc_Lights";
BA_ "ProducedBy" SG_ 1024 Light_Status_HeadlightLevel "Swc_BcmCan";
BA_ "GenSigStartValue" SG_ 1024 Light_Status_HeadlightLevel 0;
BA_ "Owner" SG_ 1025 Indicator_State_LeftOn "Swc_Indicators";
BA_ "ProducedBy" SG_ 1025 Indicator_State_LeftOn "Swc_BcmCan";
BA_ "GenSigStartValue" SG_ 1025 Indicator_State_LeftOn 0;
BA_ "Owner" SG_ 1025 Indicator_State_RightOn "Swc_Indicators";
BA_ "ProducedBy" SG_ 1025 Indicator_State_RightOn "Swc_BcmCan";
BA_ "GenSigStartValue" SG_ 1025 Indicator_State_RightOn 0;
BA_ "Owner" SG_ 1025 Indicator_State_HazardActive "Swc_Indicators";
BA_ "ProducedBy" SG_ 1025 Indicator_State_HazardActive "Swc_BcmCan";
BA_ "GenSigStartValue" SG_ 1025 Indicator_State_HazardActive 0;
BA_ "Owner" SG_ 1025 Indicator_State_BlinkPhaseHigh "Swc_Indicators";
BA_ "ProducedBy" SG_ 1025 Indicator_State_BlinkPhaseHigh "Swc_BcmCan";
BA_ "GenSigStartValue" SG_ 1025 Indicator_State_BlinkPhaseHigh 0;
BA_ "Owner" SG_ 1026 Door_Lock_Status_FrontLeftLock "Swc_DoorLock";
BA_ "ProducedBy" SG_ 1026 Door_Lock_Status_FrontLeftLock "Swc_BcmCan";
BA_ "GenSigStartValue" SG_ 1026 Door_Lock_Status_FrontLeftLock 0;
BA_ "Owner" SG_ 1026 Door_Lock_Status_FrontRightLock "Swc_DoorLock";
BA_ "ProducedBy" SG_ 1026 Door_Lock_Status_FrontRightLock "Swc_BcmCan";
BA_ "GenSigStartValue" SG_ 1026 Door_Lock_Status_FrontRightLock 0;
BA_ "Owner" SG_ 1026 Door_Lock_Status_RearLeftLock "Swc_DoorLock";
BA_ "ProducedBy" SG_ 1026 Door_Lock_Status_RearLeftLock "Swc_BcmCan";
BA_ "GenSigStartValue" SG_ 1026 Door_Lock_Status_RearLeftLock 0;
BA_ "Owner" SG_ 1026 Door_Lock_Status_RearRightLock "Swc_DoorLock";
BA_ "ProducedBy" SG_ 1026 Door_Lock_Status_RearRightLock "Swc_BcmCan";
BA_ "GenSigStartValue" SG_ 1026 Door_Lock_Status_RearRightLock 0;
BA_ "Owner" SG_ 1026 Door_Lock_Status_CentralLock "Swc_DoorLock";
BA_ "ProducedBy" SG_ 1026 Door_Lock_Status_CentralLock "Swc_BcmCan";
BA_ "GenSigStartValue" SG_ 1026 Door_Lock_Status_CentralLock 0;
BA_ "Owner" SG_ 1280 DTC_Broadcast_Status "BSW Dem module";
BA_ "ProducedBy" SG_ 1280 DTC_Broadcast_Status "Swc_CvcCom";
BA_ "GenSigStartValue" SG_ 1280 DTC_Broadcast_Status 0;
BA_ "Owner" SG_ 1280 DTC_Broadcast_ECU_Source "BSW Dem module";
BA_ "ProducedBy" SG_ 1280 DTC_Broadcast_ECU_Source "Swc_CvcCom";
BA_ "GenSigStartValue" SG_ 1280 DTC_Broadcast_ECU_Source 0;
BA_ "Owner" SG_ 1280 DTC_Broadcast_OccurrenceCount "BSW Dem module";
BA_ "ProducedBy" SG_ 1280 DTC_Broadcast_OccurrenceCount "Swc_CvcCom";
BA_ "GenSigStartValue" SG_ 1280 DTC_Broadcast_OccurrenceCount 0;
BA_ "Owner" SG_ 1280 DTC_Broadcast_FreezeFrame0 "BSW Dem module";
BA_ "ProducedBy" SG_ 1280 DTC_Broadcast_FreezeFrame0 "Swc_CvcCom";
BA_ "GenSigStartValue" SG_ 1280 DTC_Broadcast_FreezeFrame0 0;
BA_ "Owner" SG_ 1280 DTC_Broadcast_FreezeFrame1 "BSW Dem module";
BA_ "ProducedBy" SG_ 1280 DTC_Broadcast_FreezeFrame1 "Swc_CvcCom";
BA_ "GenSigStartValue" SG_ 1280 DTC_Broadcast_FreezeFrame1 0;
BA_ "GenMsgCycleTime" BO_ 1536 10;
BA_ "GenMsgCycleTime" BO_ 1537 10;
BA_ "GenMsgCycleTime" BO_ 1604 0;
BA_ "GenMsgCycleTime" BO_ 2015 0;
BA_ "GenMsgCycleTime" BO_ 2016 0;
BA_ "GenMsgCycleTime" BO_ 2017 0;
BA_ "GenMsgCycleTime" BO_ 2018 0;
BA_ "GenMsgCycleTime" BO_ 2019 0;
BA_ "GenMsgCycleTime" BO_ 2024 0;
BA_ "GenMsgCycleTime" BO_ 2025 0;
BA_ "GenMsgCycleTime" BO_ 2026 0;
BA_ "GenMsgSendType" BO_ 1536 "Cyclic";
BA_ "GenMsgSendType" BO_ 1537 "Cyclic";
BA_ "GenMsgSendType" BO_ 1604 "NoMsgSendType";
BA_ "GenMsgSendType" BO_ 2015 "NoMsgSendType";
BA_ "GenMsgSendType" BO_ 2016 "NoMsgSendType";
BA_ "GenMsgSendType" BO_ 2017 "NoMsgSendType";
BA_ "GenMsgSendType" BO_ 2018 "NoMsgSendType";
BA_ "GenMsgSendType" BO_ 2019 "NoMsgSendType";
BA_ "GenMsgSendType" BO_ 2024 "NoMsgSendType";
BA_ "GenMsgSendType" BO_ 2025 "NoMsgSendType";
BA_ "GenMsgSendType" BO_ 2026 "NoMsgSendType";
BA_ "ASIL" BO_ 1536 "QM";
BA_ "ASIL" BO_ 1537 "QM";
BA_ "ASIL" BO_ 1604 "QM";
BA_ "ASIL" BO_ 2015 "QM";
BA_ "ASIL" BO_ 2016 "QM";
BA_ "ASIL" BO_ 2017 "QM";
BA_ "ASIL" BO_ 2018 "QM";
BA_ "ASIL" BO_ 2019 "QM";
BA_ "ASIL" BO_ 2024 "QM";
BA_ "ASIL" BO_ 2025 "QM";
BA_ "ASIL" BO_ 2026 "QM";
BA_ "Owner" BO_ 1536 "SIL Integration";
BA_ "Owner" BO_ 1537 "SIL Integration";
BA_ "Owner" BO_ 1604 "BSW Dcm module";
BA_ "Owner" BO_ 2015 "BSW Dcm module";
BA_ "Owner" BO_ 2016 "BSW Dcm module";
BA_ "Owner" BO_ 2017 "BSW Dcm module";
BA_ "Owner" BO_ 2018 "BSW Dcm module";
BA_ "Owner" BO_ 2019 "BSW Dcm module";
BA_ "Owner" BO_ 2024 "BSW Dcm module";
BA_ "Owner" BO_ 2025 "BSW Dcm module";
BA_ "Owner" BO_ 2026 "BSW Dcm module";
BA_ "Owner" SG_ 1536 FZC_Virtual_Sensors_SteerAngle_Raw "Swc_FzcSensorFeeder";
BA_ "ProducedBy" SG_ 1536 FZC_Virtual_Sensors_SteerAngle_Raw "Plant_Sim (CAN)";
BA_ "GenSigStartValue" SG_ 1536 FZC_Virtual_Sensors_SteerAngle_Raw 8191;
BA_ "Owner" SG_ 1536 FZC_Virtual_Sensors_BrakePos_ADC "Swc_FzcSensorFeeder";
BA_ "ProducedBy" SG_ 1536 FZC_Virtual_Sensors_BrakePos_ADC "Plant_Sim (CAN)";
BA_ "GenSigStartValue" SG_ 1536 FZC_Virtual_Sensors_BrakePos_ADC 0;
BA_ "Owner" SG_ 1536 FZC_Virtual_Sensors_BrakeCurrent_mA "Swc_FzcSensorFeeder";
BA_ "ProducedBy" SG_ 1536 FZC_Virtual_Sensors_BrakeCurrent_mA "Plant_Sim (CAN)";
BA_ "GenSigStartValue" SG_ 1536 FZC_Virtual_Sensors_BrakeCurrent_mA 0;
BA_ "Owner" SG_ 1537 RZC_Virtual_Sensors_MotorCurrent_mA "Swc_RzcSensorFeeder";
BA_ "ProducedBy" SG_ 1537 RZC_Virtual_Sensors_MotorCurrent_mA "Plant_Sim (CAN)";
BA_ "GenSigStartValue" SG_ 1537 RZC_Virtual_Sensors_MotorCurrent_mA 0;
BA_ "Owner" SG_ 1537 RZC_Virtual_Sensors_MotorTemp_dC "Swc_RzcSensorFeeder";
BA_ "ProducedBy" SG_ 1537 RZC_Virtual_Sensors_MotorTemp_dC "Plant_Sim (CAN)";
BA_ "GenSigStartValue" SG_ 1537 RZC_Virtual_Sensors_MotorTemp_dC 250;
BA_ "Owner" SG_ 1537 RZC_Virtual_Sensors_BattVoltage_mV "Swc_RzcSensorFeeder";
BA_ "ProducedBy" SG_ 1537 RZC_Virtual_Sensors_BattVoltage_mV "Plant_Sim (CAN)";
BA_ "GenSigStartValue" SG_ 1537 RZC_Virtual_Sensors_BattVoltage_mV 12600;
BA_ "Owner" SG_ 1537 RZC_Virtual_Sensors_MotorSpeed_RPM "Swc_RzcSensorFeeder";
BA_ "ProducedBy" SG_ 1537 RZC_Virtual_Sensors_MotorSpeed_RPM "Plant_Sim (CAN)";
BA_ "GenSigStartValue" SG_ 1537 RZC_Virtual_Sensors_MotorSpeed_RPM 0;
BA_ "Owner" SG_ 1604 UDS_Resp_TCU_UDS_Data "BSW Dcm module";
BA_ "ProducedBy" SG_ 1604 UDS_Resp_TCU_UDS_Data "BSW Dcm module";
BA_ "GenSigStartValue" SG_ 1604 UDS_Resp_TCU_UDS_Data 0;
BA_ "Owner" SG_ 2015 UDS_Func_Request_UDS_Data "BSW Dcm module";
BA_ "ProducedBy" SG_ 2015 UDS_Func_Request_UDS_Data "External Tester";
BA_ "GenSigStartValue" SG_ 2015 UDS_Func_Request_UDS_Data 0;
BA_ "Owner" SG_ 2016 UDS_Phys_Req_CVC_UDS_Data "BSW Dcm module";
BA_ "ProducedBy" SG_ 2016 UDS_Phys_Req_CVC_UDS_Data "External Tester";
BA_ "GenSigStartValue" SG_ 2016 UDS_Phys_Req_CVC_UDS_Data 0;
BA_ "Owner" SG_ 2017 UDS_Phys_Req_FZC_UDS_Data "BSW Dcm module";
BA_ "ProducedBy" SG_ 2017 UDS_Phys_Req_FZC_UDS_Data "External Tester";
BA_ "GenSigStartValue" SG_ 2017 UDS_Phys_Req_FZC_UDS_Data 0;
BA_ "Owner" SG_ 2018 UDS_Phys_Req_RZC_UDS_Data "BSW Dcm module";
BA_ "ProducedBy" SG_ 2018 UDS_Phys_Req_RZC_UDS_Data "External Tester";
BA_ "GenSigStartValue" SG_ 2018 UDS_Phys_Req_RZC_UDS_Data 0;
BA_ "Owner" SG_ 2019 UDS_Phys_Req_TCU_UDS_Data "BSW Dcm module";
BA_ "ProducedBy" SG_ 2019 UDS_Phys_Req_TCU_UDS_Data "External Tester";
BA_ "GenSigStartValue" SG_ 2019 UDS_Phys_Req_TCU_UDS_Data 0;
BA_ "Owner" SG_ 2024 UDS_Resp_CVC_UDS_Data "BSW Dcm module";
BA_ "ProducedBy" SG_ 2024 UDS_Resp_CVC_UDS_Data "BSW Dcm module";
BA_ "GenSigStartValue" SG_ 2024 UDS_Resp_CVC_UDS_Data 0;
BA_ "Owner" SG_ 2025 UDS_Resp_FZC_UDS_Data "BSW Dcm module";
BA_ "ProducedBy" SG_ 2025 UDS_Resp_FZC_UDS_Data "BSW Dcm module";
BA_ "GenSigStartValue" SG_ 2025 UDS_Resp_FZC_UDS_Data 0;
BA_ "Owner" SG_ 2026 UDS_Resp_RZC_UDS_Data "BSW Dcm module";
BA_ "ProducedBy" SG_ 2026 UDS_Resp_RZC_UDS_Data "BSW Dcm module";
BA_ "GenSigStartValue" SG_ 2026 UDS_Resp_RZC_UDS_Data 0;
BA_ "E2E_DataID" BO_ 19 0;
BA_ "GenMsgCycleTimeFast" BO_ 528 10;
BA_ "GenMsgNrOfRepetition" BO_ 528 3;
BA_ "GenMsgCycleTimeFast" BO_ 529 10;
BA_ "GenMsgNrOfRepetition" BO_ 529 3;
BA_ "E2E_MaxDeltaCounter" BO_ 256 1;
BA_ "E2E_MaxDeltaCounter" BO_ 257 1;
BA_ "Satisfies" BO_ 1 "SG-008";
BA_ "Satisfies" BO_ 16 "SG-008";
BA_ "Satisfies" BO_ 17 "SG-008";
BA_ "Satisfies" BO_ 18 "SG-008";
BA_ "Satisfies" BO_ 19 "SG-008";
BA_ "Satisfies" BO_ 256 "SG-001,SG-008";
BA_ "Satisfies" BO_ 257 "SG-001";
BA_ "Satisfies" BO_ 258 "SG-003";
BA_ "Satisfies" BO_ 259 "SG-004";
BA_ "Satisfies" BO_ 512 "SG-003";
BA_ "Satisfies" BO_ 513 "SG-004";
BA_ "Satisfies" BO_ 528 "SG-004,SG-008";
BA_ "Satisfies" BO_ 529 "SG-008";
BA_ "Satisfies" BO_ 544 "SG-007";
BA_ "Satisfies" BO_ 768 "SG-002,SG-006";
BA_ "Satisfies" BO_ 769 "SG-006";
BA_ "Satisfies" BO_ 770 "SG-006";
